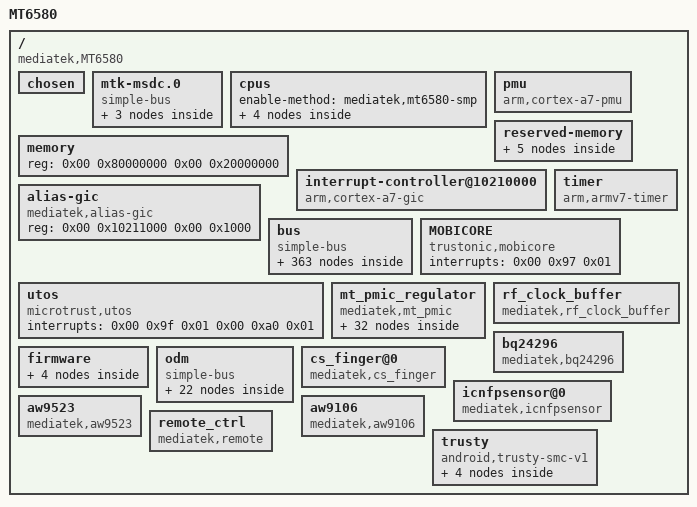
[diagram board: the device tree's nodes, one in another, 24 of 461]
/dts-v1/;

/ {
	model = "MT6580";
	compatible = "mediatek,MT6580";
	interrupt-parent = <0x01>;
	#address-cells = <0x02>;
	#size-cells = <0x02>;

	chosen {
		bootargs = "console=tty0 console=ttyMT0,921600n1 root=/dev/ram initrd=0x84000000,0x400000 loglevel=8";
		atag,videolfb-fb_base = <0x9e800000>;
		atag,videolfb-islcmfound = <0x01>;
		atag,videolfb-fps = <0x1770>;
		atag,videolfb-vramSize = <0x1800000>;
		atag,videolfb-lcmname = "nt35590_AUO";
		linux,phandle = <0x63>;
		phandle = <0x63>;
	};

	mtk-msdc.0 {
		compatible = "simple-bus";
		#address-cells = <0x01>;
		#size-cells = <0x01>;
		ranges = <0x00 0x00 0x00 0xffffffff>;

		msdc0@11120000 {
			compatible = "mediatek,mt6580-mmc";
			reg = <0x11120000 0x10000 0x10001e84 0x02>;
			interrupts = <0x00 0x26 0x08>;
			status = "okay";
			clk_src = [07];
			bus-width = <0x08>;
			max-frequency = <0xc65d400>;
			cap-mmc-highspeed;
			msdc-sys-suspend;
			mmc-hs200-1_8v;
			non-removable;
			pinctl = <0x02>;
			register_setting = <0x03>;
			host_function = [00];
			bootable;
			linux,phandle = <0x64>;
			phandle = <0x64>;
		};

		msdc1@11130000 {
			compatible = "mediatek,mt6580-mmc";
			reg = <0x11130000 0x10000 0x10001e84 0x02>;
			interrupts = <0x00 0x27 0x08>;
			cd-gpios = <0x04 0x14 0x00>;
			status = "okay";
			clk_src = [02];
			bus-width = <0x04>;
			max-frequency = <0xc65d400>;
			msdc-sys-suspend;
			cap-sd-highspeed;
			sd-uhs-sdr12;
			sd-uhs-sdr25;
			sd-uhs-sdr50;
			sd-uhs-sdr104;
			pinctrl-names = "default\0insert_cfg";
			pinctrl-0 = <0x05>;
			pinctrl-1 = <0x06>;
			pinctl = <0x07>;
			pinctl_sdr104 = <0x08>;
			pinctl_sdr50 = <0x09>;
			pinctl_ddr50 = <0x0a>;
			register_setting = <0x0b>;
			host_function = [01];
			cd_level = [00];
			linux,phandle = <0x65>;
			phandle = <0x65>;
		};

		default {
			compatible = "mediatek,msdc1_ins-eint";
			linux,phandle = <0x66>;
			phandle = <0x66>;
		};
	};

	cpus {
		#address-cells = <0x01>;
		#size-cells = <0x00>;
		enable-method = "mediatek,mt6580-smp";

		cpu@0 {
			device_type = "cpu";
			compatible = "arm,cortex-a7";
			reg = <0x00>;
			clock-frequency = <0x6553f100>;
			linux,phandle = <0x67>;
			phandle = <0x67>;
		};

		cpu@1 {
			device_type = "cpu";
			compatible = "arm,cortex-a7";
			reg = <0x01>;
			clock-frequency = <0x6553f100>;
			linux,phandle = <0x68>;
			phandle = <0x68>;
		};

		cpu@2 {
			device_type = "cpu";
			compatible = "arm,cortex-a7";
			reg = <0x02>;
			clock-frequency = <0x6553f100>;
			linux,phandle = <0x69>;
			phandle = <0x69>;
		};

		cpu@3 {
			device_type = "cpu";
			compatible = "arm,cortex-a7";
			reg = <0x03>;
			clock-frequency = <0x6553f100>;
			linux,phandle = <0x6a>;
			phandle = <0x6a>;
		};
	};

	pmu {
		compatible = "arm,cortex-a7-pmu";
		interrupts = <0x00 0x04 0x08 0x00 0x05 0x08 0x00 0x06 0x08 0x00 0x07 0x08>;
	};

	memory {
		device_type = "memory";
		reg = <0x00 0x80000000 0x00 0x20000000>;
	};

	reserved-memory {
		#address-cells = <0x02>;
		#size-cells = <0x02>;
		ranges;
		linux,phandle = <0x6b>;
		phandle = <0x6b>;

		consys-reserve-memory {
			compatible = "mediatek,consys-reserve-memory";
			no-map;
			size = <0x00 0x200000>;
			alignment = <0x00 0x200000>;
		};

		reserve-memory-ccci_md1 {
			compatible = "mediatek,reserve-memory-ccci_md1";
			no-map;
			size = <0x00 0x1800000>;
			alignment = <0x00 0x2000000>;
			alloc-ranges = <0x00 0x80000000 0x00 0x80000000>;
		};

		pstore-reserved-memory@83f10000 {
			compatible = "mediatek,pstore";
			reg = <0x00 0x83f10000 0x00 0xe0000>;
		};

		ram_console-reserved-memory@83f00000 {
			compatible = "mediatek,ram_console";
			reg = <0x00 0x83f00000 0x00 0x10000>;
		};

		minirdump-reserved-memory@83ff0000 {
			compatible = "mediatek, minirdump";
			reg = <0x00 0x83ff0000 0x00 0x10000>;
		};
	};

	interrupt-controller@10210000 {
		compatible = "arm,cortex-a7-gic";
		#interrupt-cells = <0x03>;
		#address-cells = <0x00>;
		interrupt-controller;
		reg = <0x00 0x10211000 0x00 0x1000 0x00 0x10212000 0x00 0x1000 0x00 0x10200100 0x00 0x1000>;
		interrupts = <0x01 0x09 0xf04>;
		linux,phandle = <0x01>;
		phandle = <0x01>;
	};

	alias-gic {
		compatible = "mediatek,alias-gic";
		reg = <0x00 0x10211000 0x00 0x1000>;
	};

	timer {
		compatible = "arm,armv7-timer";
		interrupts = <0x01 0x0d 0x08 0x01 0x0e 0x08 0x01 0x0b 0x08 0x01 0x0a 0x08>;
		clock-frequency = <0xc65d40>;
	};

	bus {
		compatible = "simple-bus";
		#address-cells = <0x01>;
		#size-cells = <0x01>;
		ranges = <0x00 0x00 0x00 0xffffffff>;
		linux,phandle = <0x6c>;
		phandle = <0x6c>;

		chipid@08000000 {
			compatible = "mediatek,chipid";
			reg = <0x8000000 0x04 0x8000004 0x04 0x8000008 0x04 0x800000c 0x04>;
		};

		TOPCKGEN@0x10000000 {
			compatible = "mediatek,TOPCKGEN";
			reg = <0x10000000 0x1000>;
		};

		INFRACFG_AO@0x10001000 {
			compatible = "mediatek,INFRACFG_AO";
			reg = <0x10001000 0x1000>;
		};

		bat_meter {
			compatible = "mediatek,bat_meter";
			linux,phandle = <0x6d>;
			phandle = <0x6d>;
		};

		BAT_NOTIFY {
			compatible = "mediatek,bat_notify";
		};

		bat_comm {
			compatible = "mediatek,battery";
			linux,phandle = <0x6e>;
			phandle = <0x6e>;
		};

		keypad@10002000 {
			compatible = "mediatek,mt6580-keypad";
			reg = <0x10002000 0x1000>;
			interrupts = <0x00 0x6d 0x02>;
			mediatek,kpd-key-debounce = <0x400>;
			mediatek,kpd-sw-pwrkey = <0x74>;
			mediatek,kpd-hw-pwrkey = <0x08>;
			mediatek,kpd-sw-rstkey = <0x66>;
			mediatek,kpd-hw-rstkey = <0x11>;
			mediatek,kpd-use-extend-type = <0x00>;
			mediatek,kpd-hw-map-num = <0x48>;
			mediatek,kpd-hw-init-map = <0x00 0x00 0x00 0x00 0x00 0x00 0x00 0x00 0x00 0x00 0x00 0x00 0x00 0x00 0x00 0x00 0x00 0x00 0x9e 0x66 0x8b 0x72 0x73 0x00 0x00 0x00 0x00 0x67 0x6c 0x69 0x6a 0x1c 0x00 0x00 0x00 0x00 0x00 0x00 0x00 0x00 0x00 0x00 0x00 0x00 0x00 0x00 0x00 0x00 0x00 0x00 0x00 0x00 0x00 0x00 0x00 0x00 0x00 0x00 0x00 0x00 0x00 0x00 0x00 0x00 0x00 0x00 0x00 0x00 0x00 0x00 0x00 0x00>;
			mediatek,kpd-pwrkey-eint-gpio = <0x00>;
			mediatek,kpd-pwkey-gpio-din = <0x00>;
			mediatek,kpd-hw-dl-key0 = <0x16>;
			mediatek,kpd-hw-dl-key1 = <0x15>;
			mediatek,kpd-hw-dl-key2 = <0x08>;
			mediatek,kpd-hw-recovery-key = <0x16>;
			mediatek,kpd-hw-factory-key = <0x15>;
			status = "okay";
			linux,phandle = <0x6f>;
			phandle = <0x6f>;
		};

		PERICFG@0x10003000 {
			compatible = "mediatek,PERICFG";
			reg = <0x10003000 0x1000>;
		};

		RESERVED@0x10004000 {
			compatible = "mediatek,RESERVED";
			reg = <0x10004000 0x1000>;
		};

		gpio {
			compatible = "mediatek,gpio_usage_mapping";
			GPIO_SIM1_SCLK = <0x16>;
			GPIO_SIM1_SIO = <0x17>;
			GPIO_SIM2_SIO = <0x18>;
			GPIO_SIM2_SCLK = <0x19>;
			linux,phandle = <0x70>;
			phandle = <0x70>;
		};

		gpio@0x10005000 {
			compatible = "mediatek,gpio";
			reg = <0x10005000 0x1000>;
			linux,phandle = <0x71>;
			phandle = <0x71>;
		};

		SLEEP@0x10006000 {
			compatible = "mediatek,SLEEP";
			reg = <0x10006000 0x1000>;
			interrupts = <0x00 0x58 0x08 0x00 0x59 0x08 0x00 0x5a 0x08 0x00 0x5b 0x08>;
		};

		TOPRGU@0x10007000 {
			compatible = "mediatek,TOPRGU";
			reg = <0x10007000 0x1000>;
			interrupts = <0x00 0x9d 0x02>;
		};

		APXGPT@0x10008000 {
			compatible = "mediatek,APXGPT";
			reg = <0x10008000 0x1000>;
			interrupts = <0x00 0x5c 0x08>;
			clock-frequency = <0xc65d40>;
		};

		EFUSEC@0x10009000 {
			compatible = "mediatek,EFUSEC";
			reg = <0x10009000 0x1000>;
		};

		hacc@0x1000A000 {
			compatible = "mediatek,hacc";
			reg = <0x1000a000 0x1000>;
			interrupts = <0x00 0x6e 0x00>;
		};

		cpu_dbgapb@10170000 {
			compatible = "mediatek,hw_dbg";
			num = <0x04>;
			reg = <0x10170000 0x2000 0x10172000 0x2000 0x10174000 0x2000 0x10176000 0x2000>;
			linux,phandle = <0x72>;
			phandle = <0x72>;
		};

		eintc@1000b000 {
			compatible = "mediatek,mt-eic";
			reg = <0x1000b000 0x1000>;
			interrupts = <0x00 0x5e 0x04>;
			#interrupt-cells = <0x02>;
			interrupt-controller;
			mediatek,max_eint_num = <0x1a>;
			mediatek,mapping_table_entry = <0x53>;
			mediatek,mapping_table = <0x00 0x00 0x01 0x01 0x02 0x02 0x03 0x03 0x04 0x04 0x05 0x05 0x06 0x06 0x07 0x07 0x08 0x08 0x09 0x09 0x0a 0x0a 0x0b 0x0b 0x0c 0x0c 0x0d 0x0d 0x0e 0x0e 0x0f 0x0f 0x10 0x00 0x11 0x01 0x12 0x02 0x13 0x03 0x14 0x04 0x15 0x05 0x16 0x06 0x17 0x07 0x18 0x08 0x19 0x09 0x1a 0x0a 0x1b 0x0b 0x1c 0x0c 0x1d 0x0d 0x1e 0x0e 0x1f 0x0f 0x20 0x00 0x21 0x01 0x22 0x02 0x23 0x03 0x24 0x04 0x25 0x05 0x26 0x06 0x27 0x07 0x28 0x08 0x29 0x09 0x2a 0x0a 0x2b 0x0b 0x2c 0x0c 0x2d 0x0d 0x2e 0x0e 0x2f 0x0f 0x30 0x00 0x31 0x01 0x32 0x02 0x33 0x03 0x34 0x03 0x35 0x04 0x36 0x05 0x37 0x06 0x38 0x07 0x39 0x08 0x3a 0x0a 0x3b 0x0b 0x3c 0x0c 0x3d 0x0d 0x3e 0x0e 0x3f 0x0f 0x40 0x00 0x41 0x01 0x42 0x02 0x43 0x03 0x44 0x10 0x45 0x04 0x46 0x05 0x47 0x06 0x48 0x07 0x49 0x08 0x4a 0x09 0x4b 0x0a 0x4c 0x0b 0x4d 0x0c 0x4e 0x0d 0x51 0x00 0x52 0x01 0x53 0x02 0x54 0x03>;
			mediatek,builtin_entry = <0x0b>;
			mediatek,builtin_mapping = <0x00 0x03 0x14 0x01 0x03 0x12 0x07 0x04 0x14 0x08 0x04 0x12 0x09 0x03 0x14 0x0a 0x03 0x12 0x18 0x05 0x14 0x19 0x05 0x12 0x4d 0x02 0x14 0x4e 0x02 0x12 0x0d 0x01 0x11>;
			linux,phandle = <0x0c>;
			phandle = <0x0c>;

			pmic@13 {
				compatible = "mediatek, pmic-eint";
				interrupt-parent = <0x0c>;
				interrupts = <0x0d 0x04>;
				debounce = <0x0d 0x3e8>;
			};
		};

		ap_ccif0@1000C000 {
			compatible = "mediatek,ap_ccif0";
			reg = <0x1000c000 0x1000 0x1000d000 0x1000>;
			interrupts = <0x00 0x5d 0x08 0x00 0x98 0x02>;
			mediatek,ccif_capability = <0x02>;
			mediatek,md_smem_size = <0x200000>;
			linux,phandle = <0x73>;
			phandle = <0x73>;
		};

		MCUSYS_CFGREG@0x1020000 {
			compatible = "mediatek,MCUSYS_CFGREG_BASE";
			reg = <0x1020000 0x200>;
		};

		mcucfg@10200000 {
			compatible = "mediatek,mt6580-mcucfg";
			reg = <0x10200000 0x200>;
			linux,phandle = <0x74>;
			phandle = <0x74>;
		};

		AES@0x1000E000 {
			compatible = "mediatek,AES";
			reg = <0x1000e000 0x1000>;
		};

		PWRAP@0x1000F000 {
			compatible = "mediatek,PWRAP";
			reg = <0x1000f000 0x1000>;
			interrupts = <0x00 0x6c 0x00>;
		};

		DEVAPC_AO@0x10010000 {
			compatible = "mediatek,DEVAPC_AO";
			reg = <0x10010000 0x1000>;
		};

		MIPI_CONFG@0x10011000 {
			compatible = "mediatek,MIPI_CONFG";
			reg = <0x10011000 0x1000>;
		};

		INFRA_MBIST@0x10012000 {
			compatible = "mediatek,INFRA_MBIST";
			reg = <0x10012000 0x1000>;
		};

		RESERVED@0x10013000 {
			compatible = "mediatek,RESERVED";
			reg = <0x10013000 0x1000>;
		};

		IOCFG_T@0x10014000 {
			compatible = "mediatek,IOCFG_T";
			reg = <0x10014000 0x1000>;
		};

		IOCFG_B@0x10015000 {
			compatible = "mediatek,IOCFG_B";
			reg = <0x10015000 0x1000>;
		};

		IOCFG_L@0x10016000 {
			compatible = "mediatek,IOCFG_L";
			reg = <0x10016000 0x1000>;
		};

		IOCFG_R@0x10017000 {
			compatible = "mediatek,IOCFG_R";
			reg = <0x10017000 0x1000>;
		};

		APMIXED@0x10018000 {
			compatible = "mediatek,APMIXED";
			reg = <0x10018000 0x1000>;
		};

		MCUCFG@0x10200000 {
			compatible = "mediatek,MCUCFG";
			reg = <0x10200000 0x1000>;
		};

		INFRACFG@0x10201000 {
			compatible = "mediatek,INFRACFG";
			reg = <0x10201000 0x1000>;
		};

		sys_cirq@10202000 {
			compatible = "mediatek,mt6580-sys_cirq\0mediatek,mt6735-sys_cirq";
			reg = <0x10202000 0x1000>;
			interrupts = <0x00 0x9e 0x08>;
			mediatek,cirq_num = <0x7e>;
			mediatek,spi_start_offset = <0x20>;
			linux,phandle = <0x75>;
			phandle = <0x75>;
		};

		m4u@10203000 {
			cell-index = <0x00>;
			compatible = "mediatek,m4u";
			reg = <0x10203000 0x1000>;
			interrupts = <0x00 0x51 0x08>;
		};

		DEVAPC@0x10204000 {
			compatible = "mediatek,DEVAPC";
			reg = <0x10204000 0x1000>;
			interrupts = <0x00 0x4a 0x08>;
		};

		EMI@0x10205000 {
			compatible = "mediatek,EMI";
			reg = <0x10205000 0x1000>;
			interrupts = <0x00 0x4c 0x04>;
		};

		DRAMC_NAO@0x10206000 {
			compatible = "mediatek,DRAMC_NAO";
			reg = <0x10206000 0x1000>;
		};

		DRAMC0@0x10207000 {
			compatible = "mediatek,DRAMC0";
			reg = <0x10207000 0x1000>;
		};

		DDRPHY@0x10208000 {
			compatible = "mediatek,DDRPHY";
			reg = <0x10208000 0x1000>;
		};

		SRAMROM@0x10209000 {
			compatible = "mediatek,SRAMROM";
			reg = <0x10209000 0x1000>;
		};

		gce@1020a000 {
			compatible = "mediatek,gce";
			reg = <0x1020a000 0x1000>;
			interrupts = <0x00 0x55 0x08 0x00 0x56 0x08>;
			disp_mutex_reg = <0x14015000 0x1000>;
			g3d_config_base = <0x13000000 0x00 0xffff0000>;
			mmsys_config_base = <0x14000000 0x01 0xffff0000>;
			disp_dither_base = <0x14010000 0x02 0xffff0000>;
			mm_na_base = <0x14020000 0x03 0xffff0000>;
			imgsys_base = <0x15000000 0x04 0xffff0000>;
			vdec_gcon_base = <0x16000000 0x05 0xffff0000>;
			venc_gcon_base = <0x17000000 0x06 0xffff0000>;
			conn_peri_base = <0x18000000 0x07 0xffff0000>;
			topckgen_base = <0x10000000 0x08 0xffff0000>;
			kp_base = <0x10010000 0x09 0xffff0000>;
			scp_sram_base = <0x10020000 0x0a 0xffff0000>;
			infra_na3_base = <0x10030000 0x0b 0xffff0000>;
			infra_na4_base = <0x10040000 0x0c 0xffff0000>;
			scp_base = <0x10050000 0x0d 0xffff0000>;
			mcucfg_base = <0x10200000 0x0e 0xffff0000>;
			gcpu_base = <0x10210000 0x0f 0xffff0000>;
			usb0_base = <0x11200000 0x10 0xffff0000>;
			usb_sif_base = <0x11210000 0x11 0xffff0000>;
			audio_base = <0x11220000 0x12 0xffff0000>;
			msdc0_base = <0x11230000 0x13 0xffff0000>;
			msdc1_base = <0x11240000 0x14 0xffff0000>;
			msdc2_base = <0x11250000 0x15 0xffff0000>;
			msdc3_base = <0x11260000 0x16 0xffff0000>;
			pwm_sw_base = <0x1100f000 0x63 0xfffff000>;
			mdp_rdma0_sof = <0x00>;
			mdp_rsz0_sof = <0x01>;
			mdp_rsz1_sof = <0x02>;
			mdp_tdshp_sof = <0x03>;
			mdp_wdma_sof = <0x04>;
			mdp_wrot_sof = <0x05>;
			disp_ovl0_sof = <0x06>;
			disp_rdma0_sof = <0x08>;
			disp_wdma0_sof = <0x0a>;
			disp_color_sof = <0x0c>;
			disp_aal_sof = <0x0d>;
			disp_gamma_sof = <0x0e>;
			disp_dither_sof = <0x0f>;
			disp_pwm0_sof = <0x11>;
			mdp_rdma0_frame_done = <0x12>;
			mdp_rsz0_frame_done = <0x13>;
			mdp_rsz1_frame_done = <0x14>;
			mdp_tdshp_frame_done = <0x15>;
			mdp_wdma_frame_done = <0x16>;
			mdp_wrot_write_frame_done = <0x17>;
			mdp_wrot_read_frame_done = <0x18>;
			disp_ovl0_frame_done = <0x19>;
			disp_rdma0_frame_done = <0x1b>;
			disp_wdma0_frame_done = <0x1d>;
			disp_color_frame_done = <0x1f>;
			disp_aal_frame_done = <0x20>;
			disp_gamma_frame_done = <0x21>;
			disp_dither_frame_done = <0x22>;
			disp_dsi0_frame_done = <0x25>;
			stream_done_0 = <0x26>;
			stream_done_1 = <0x27>;
			stream_done_2 = <0x28>;
			stream_done_3 = <0x29>;
			stream_done_4 = <0x2a>;
			stream_done_5 = <0x2b>;
			stream_done_6 = <0x2c>;
			stream_done_7 = <0x2d>;
			stream_done_8 = <0x2e>;
			stream_done_9 = <0x2f>;
			buf_underrun_event_0 = <0x30>;
			dsi0_te_event = <0x32>;
			isp_frame_done_p2_1 = <0x42>;
			isp_frame_done_p2_0 = <0x43>;
			seninf_cam0_fifo_full = <0x49>;
			apxgpt2_count = <0x10008028>;
		};

		bus_dbg@1020b000 {
			compatible = "mediatek,bus_dbg-v2";
			reg = <0x1020b000 0x1000>;
			interrupts = <0x00 0x49 0x08>;
			two_stage_timeout = <0x01>;
		};

		TRNG@0x1020C000 {
			compatible = "mediatek,TRNG";
			reg = <0x1020c000 0x1000>;
			interrupts = <0x00 0x57 0x08>;
		};

		MCUCFG_BIU@0x1020D000 {
			compatible = "mediatek,MCUCFG_BIU";
			reg = <0x1020d000 0x1000>;
		};

		DBGSYS_DEM@0x1011A000 {
			compatible = "mediatek,DBGSYS_DEM";
			reg = <0x1011a000 0x1000>;
		};

		DBGSYS_CTI@0x10112000 {
			compatible = "mediatek,DBGSYS_CTI";
			reg = <0x10112000 0x1000>;
		};

		DBGSYS_DAPROM@0x10110000 {
			compatible = "mediatek,DBGSYS_DAPROM";
			reg = <0x10110000 0x1000>;
		};

		DBGSYS_CPU@0x10160000 {
			compatible = "mediatek,DBGSYS_CPU";
			reg = <0x10160000 0x20000>;
		};

		DBGSYS_MDSYS@0x10120000 {
			compatible = "mediatek,DBGSYS_MDSYS";
			reg = <0x10120000 0x10000>;
		};

		dma@0x11000000 {
			compatible = "mediatek,ap_dma";
			reg = <0x11000000 0x1000>;
			interrupts = <0x00 0x30 0x08>;
			linux,phandle = <0x76>;
			phandle = <0x76>;
		};

		NFI@0x11001000 {
			compatible = "mediatek,NFI";
			reg = <0x11001000 0x1000>;
			interrupts = <0x00 0x2f 0x08>;
		};

		NFIECC@0x11002000 {
			compatible = "mediatek,NFIECC";
			reg = <0x11002000 0x1000>;
			interrupts = <0x00 0x2e 0x08>;
		};

		adc_hw@11003000 {
			compatible = "mediatek,mt6735-auxadc";
			reg = <0x11003000 0x1000>;
			interrupts = <0x00 0x23 0x02>;
			linux,phandle = <0x77>;
			phandle = <0x77>;

			adc_channel@ {
				compatible = "mediatek,adc_channel";
				mediatek,temperature0 = <0x00>;
				mediatek,temperature1 = <0x01>;
				status = "okay";
			};
		};

		FHCTL@0x11004000 {
			compatible = "mediatek,FHCTL";
			reg = <0x11004000 0x1000>;
		};

		AP_UART0@0x11005000 {
			cell-index = <0x00>;
			compatible = "mediatek,AP_UART0";
			reg = <0x11005000 0x1000>;
			interrupts = <0x00 0x2c 0x08>;
		};

		AP_UART1@0x11006000 {
			cell-index = <0x01>;
			compatible = "mediatek,AP_UART1";
			reg = <0x11006000 0x1000>;
			interrupts = <0x00 0x2d 0x08>;
		};

		AP_DMA_UART0_TX@0x11000480 {
			compatible = "mediatek,AP_DMA_UART0_TX";
			reg = <0x11000480 0x80>;
			interrupts = <0x00 0x38 0x08>;
		};

		AP_DMA_UART0_RX@0x11000500 {
			compatible = "mediatek,AP_DMA_UART0_RX";
			reg = <0x11000500 0x80>;
			interrupts = <0x00 0x39 0x08>;
		};

		AP_DMA_UART1_TX@0x11000580 {
			compatible = "mediatek,AP_DMA_UART1_TX";
			reg = <0x11000580 0x80>;
			interrupts = <0x00 0x3a 0x08>;
		};

		AP_DMA_UART1_RX@0x11000600 {
			compatible = "mediatek,AP_DMA_UART1_RX";
			reg = <0x11000600 0x80>;
			interrupts = <0x00 0x3b 0x08>;
		};

		PWM@0x11008000 {
			compatible = "mediatek,PWM";
			reg = <0x11008000 0x1000>;
			interrupts = <0x00 0x24 0x08>;
		};

		syscfg_pctl_a@0x10005000 {
			compatible = "mediatek,mt6580-pctl-a-syscfg\0syscon";
			reg = <0x10211000 0x1000>;
			linux,phandle = <0x0d>;
			phandle = <0x0d>;
		};

		pinctrl@0x10005000 {
			compatible = "mediatek,mt6580-pinctrl";
			reg = <0x10005000 0x1000>;
			mediatek,pctl-regmap = <0x0d>;
			pins-are-numbered;
			gpio-controller;
			#gpio-cells = <0x02>;
			linux,phandle = <0x04>;
			phandle = <0x04>;

			mmc0@default {
				linux,phandle = <0x02>;
				phandle = <0x02>;

				pins_cmd {
					drive-strength = [02];
				};

				pins_dat {
					drive-strength = [02];
				};

				pins_clk {
					drive-strength = [02];
				};

				pins_rst {
					drive-strength = [02];
				};

				pins_ds {
					drive-strength = [02];
				};
			};

			mmc0@register_default {
				dat0rddly = [00];
				dat1rddly = [00];
				dat2rddly = [00];
				dat3rddly = [00];
				dat4rddly = [00];
				dat5rddly = [00];
				dat6rddly = [00];
				dat7rddly = [00];
				datwrddly = [00];
				cmdrrddly = [00];
				cmdrddly = [00];
				cmd_edge = [01];
				rdata_edge = [01];
				wdata_edge = [01];
				ett-hs200-cells = <0x0c>;
				ett-hs200-default = <0xb0 0x380 0x00 0xb0 0x7c00 0x00 0xb4 0x38 0x01 0x04 0x02 0x01 0xf0 0x1f0000 0x00 0xf0 0x7c00000 0x00 0xb4 0x07 0x01 0xf0 0x1f 0x00 0x04 0x100 0x01 0xf8 0x1f000000 0x00 0xf0 0x1f00 0x00 0xb0 0x08 0x01>;
				linux,phandle = <0x03>;
				phandle = <0x03>;
			};

			mmc1@default {
				linux,phandle = <0x07>;
				phandle = <0x07>;

				pins_cmd {
					drive-strength = [03];
				};

				pins_dat {
					drive-strength = [03];
				};

				pins_clk {
					drive-strength = [03];
				};
			};

			mmc1_ins_default {
				linux,phandle = <0x05>;
				phandle = <0x05>;
			};

			mmc1_ins_cfg {
				linux,phandle = <0x06>;
				phandle = <0x06>;

				pins_insert {
					pins = <0x1406>;
					input-schmitt-enable = <0x01>;
					slew-rate = <0x00>;
					bias-pull-up = <0x00>;
				};
			};

			mmc1@sdr104 {
				linux,phandle = <0x08>;
				phandle = <0x08>;

				pins_cmd {
					drive-strength = [02];
				};

				pins_dat {
					drive-strength = [02];
				};

				pins_clk {
					drive-strength = [03];
				};
			};

			mmc1@sdr50 {
				linux,phandle = <0x09>;
				phandle = <0x09>;

				pins_cmd {
					drive-strength = [02];
				};

				pins_dat {
					drive-strength = [02];
				};

				pins_clk {
					drive-strength = [03];
				};
			};

			mmc1@ddr50 {
				linux,phandle = <0x0a>;
				phandle = <0x0a>;

				pins_cmd {
					drive-strength = [02];
				};

				pins_dat {
					drive-strength = [02];
				};

				pins_clk {
					drive-strength = [03];
				};
			};

			mmc1@register_default {
				dat0rddly = [00];
				dat1rddly = [00];
				dat2rddly = [00];
				dat3rddly = [00];
				datwrddly = [00];
				cmdrrddly = [00];
				cmdrddly = [00];
				cmd_edge = [01];
				rdata_edge = [01];
				wdata_edge = [01];
				linux,phandle = <0x0b>;
				phandle = <0x0b>;
			};

			alspspincfg {
				linux,phandle = <0x0f>;
				phandle = <0x0f>;

				pins_cmd_dat {
					pins = <0x606>;
					slew-rate = <0x00>;
					bias-pull-up = <0x00>;
				};
			};

			alspsdefaultcfg {
				linux,phandle = <0x0e>;
				phandle = <0x0e>;
			};

			eint0default {
				linux,phandle = <0x17>;
				phandle = <0x17>;
			};

			eint@0 {
				linux,phandle = <0x18>;
				phandle = <0x18>;

				pins_cmd_dat {
					pins = <0x306>;
					slew-rate = <0x00>;
					bias-disable;
				};
			};

			toucheint5default {
				linux,phandle = <0x11>;
				phandle = <0x11>;
			};

			toucheint@5 {
				linux,phandle = <0x12>;
				phandle = <0x12>;

				pins_cmd_dat {
					pins = <0x506>;
					slew-rate = <0x00>;
					bias-disable;
				};
			};

			eintoutput0 {
				linux,phandle = <0x13>;
				phandle = <0x13>;

				pins_cmd_dat {
					pins = <0x500>;
					slew-rate = <0x01>;
					output-low;
				};
			};

			eintoutput1 {
				linux,phandle = <0x14>;
				phandle = <0x14>;

				pins_cmd_dat {
					pins = <0x500>;
					slew-rate = <0x01>;
					output-high;
				};
			};

			rstoutput0 {
				linux,phandle = <0x15>;
				phandle = <0x15>;

				pins_cmd_dat {
					pins = <0x200>;
					slew-rate = <0x01>;
					output-low;
				};
			};

			rstoutput1 {
				linux,phandle = <0x16>;
				phandle = <0x16>;

				pins_cmd_dat {
					pins = <0x200>;
					slew-rate = <0x01>;
					output-high;
				};
			};

			audiodefault {
				linux,phandle = <0x23>;
				phandle = <0x23>;
			};

			pmicclkmode0 {
				linux,phandle = <0x24>;
				phandle = <0x24>;

				pins_cmd0_dat {
					pins = <0x1a00>;
				};

				pins_cmd1_dat {
					pins = <0x1c00>;
				};

				pins_cmd2_dat {
					pins = <0x1b00>;
				};
			};

			pmicclkmode1 {
				linux,phandle = <0x25>;
				phandle = <0x25>;

				pins_cmd0_dat {
					pins = <0x1a01>;
				};

				pins_cmd1_dat {
					pins = <0x1c01>;
				};

				pins_cmd2_dat {
					pins = <0x1b01>;
				};
			};

			mode_te_gpio {
				linux,phandle = <0x3c>;
				phandle = <0x3c>;

				pins_cmd_dat {
					pins = <0x4400>;
				};
			};

			mode_te_te {
				linux,phandle = <0x3d>;
				phandle = <0x3d>;

				pins_cmd_dat {
					pins = <0x4401>;
				};
			};

			lcm_rst_out0_gpio {
				linux,phandle = <0x3e>;
				phandle = <0x3e>;

				pins_cmd_dat {
					pins = <0x4601>;
					slew-rate = <0x01>;
					output-low;
				};
			};

			lcm_rst_out1_gpio {
				linux,phandle = <0x3f>;
				phandle = <0x3f>;

				pins_cmd_dat {
					pins = <0x4601>;
					slew-rate = <0x01>;
					output-high;
				};
			};

			pwm_test_pin_mux_gpio66 {
				linux,phandle = <0x40>;
				phandle = <0x40>;

				pins_cmd_dat {
					pins = <0x4201>;
					slew-rate = <0x01>;
				};
			};

			mtkfb_default {
				linux,phandle = <0x3b>;
				phandle = <0x3b>;
			};

			cam0@0 {
				linux,phandle = <0x2b>;
				phandle = <0x2b>;

				pins_cmd_dat {
					pins = <0x4900>;
					slew-rate = <0x01>;
					output-low;
				};
			};

			cam0@1 {
				linux,phandle = <0x2c>;
				phandle = <0x2c>;

				pins_cmd_dat {
					pins = <0x4900>;
					slew-rate = <0x01>;
					output-high;
				};
			};

			cam0@2 {
				linux,phandle = <0x2d>;
				phandle = <0x2d>;

				pins_cmd_dat {
					pins = <0x4700>;
					slew-rate = <0x01>;
					output-low;
				};
			};

			cam0@3 {
				linux,phandle = <0x2e>;
				phandle = <0x2e>;

				pins_cmd_dat {
					pins = <0x4700>;
					slew-rate = <0x01>;
					output-high;
				};
			};

			cam1@0 {
				linux,phandle = <0x2f>;
				phandle = <0x2f>;

				pins_cmd_dat {
					pins = <0x4c00>;
					slew-rate = <0x01>;
					output-low;
				};
			};

			cam1@1 {
				linux,phandle = <0x30>;
				phandle = <0x30>;

				pins_cmd_dat {
					pins = <0x4c00>;
					slew-rate = <0x01>;
					output-high;
				};
			};

			cam1@2 {
				linux,phandle = <0x31>;
				phandle = <0x31>;

				pins_cmd_dat {
					pins = <0x4a00>;
					slew-rate = <0x01>;
					output-low;
				};
			};

			cam1@3 {
				linux,phandle = <0x32>;
				phandle = <0x32>;

				pins_cmd_dat {
					pins = <0x4a00>;
					slew-rate = <0x01>;
					output-high;
				};
			};

			cam@0 {
				linux,phandle = <0x33>;
				phandle = <0x33>;
			};

			cam@1 {
				linux,phandle = <0x34>;
				phandle = <0x34>;
			};

			camdefault {
				linux,phandle = <0x2a>;
				phandle = <0x2a>;
			};

			cam1serial@0 {
				linux,phandle = <0x35>;
				phandle = <0x35>;

				pins_cmd_dat {
					pins = <0x2302>;
				};

				pins_cmd_dat1 {
					pins = <0x2402>;
				};

				pins_cmd_dat2 {
					pins = <0x2502>;
				};

				pins_cmd_dat3 {
					pins = <0x2602>;
				};

				pins_cmd_dat4 {
					pins = <0x2702>;
				};
			};

			cam1mipi@0 {
				linux,phandle = <0x36>;
				phandle = <0x36>;

				pins_cmd_dat {
					pins = <0x2301>;
				};

				pins_cmd_dat1 {
					pins = <0x2401>;
				};

				pins_cmd_dat2 {
					pins = <0x2501>;
				};

				pins_cmd_dat3 {
					pins = <0x2601>;
				};

				pins_cmd_dat4 {
					pins = <0x2701>;
				};

				pins_cmd_dat5 {
					pins = <0x2801>;
				};
			};

			mclk1enable@0 {
				linux,phandle = <0x37>;
				phandle = <0x37>;

				pins_cmd_dat {
					pins = <0x4b01>;
				};
			};

			mclk1disable@0 {
				linux,phandle = <0x38>;
				phandle = <0x38>;

				pins_cmd_dat {
					pins = <0x4b00>;
				};
			};

			mclk2enable@0 {
				linux,phandle = <0x39>;
				phandle = <0x39>;

				pins_cmd_dat {
					pins = <0x4b01>;
				};
			};

			mclk2disable@0 {
				linux,phandle = <0x3a>;
				phandle = <0x3a>;

				pins_cmd_dat {
					pins = <0x4b00>;
				};
			};

			consys_default {
				linux,phandle = <0x1d>;
				phandle = <0x1d>;
			};

			gpslna@0 {
				linux,phandle = <0x1e>;
				phandle = <0x1e>;

				pins_cmd_dat {
					pins = <0x1500>;
					slew-rate = <0x00>;
					bias-disable;
					output-low;
				};
			};

			gpslna@1 {
				linux,phandle = <0x1f>;
				phandle = <0x1f>;

				pins_cmd_dat {
					pins = <0x1500>;
					slew-rate = <0x01>;
					output-high;
				};
			};

			gpslna@2 {
				linux,phandle = <0x20>;
				phandle = <0x20>;

				pins_cmd_dat {
					pins = <0x1500>;
					slew-rate = <0x01>;
					output-low;
				};
			};

			aw@0 {
				linux,phandle = <0x55>;
				phandle = <0x55>;
			};

			aw@1 {
				linux,phandle = <0x56>;
				phandle = <0x56>;

				pins_cmd_dat {
					pins = <0x4800>;
					slew-rate = <0x01>;
					output-high;
				};
			};

			aw@2 {
				linux,phandle = <0x57>;
				phandle = <0x57>;

				pins_cmd_dat {
					pins = <0x4800>;
					slew-rate = <0x01>;
					output-low;
				};
			};

			www@0 {
				linux,phandle = <0x58>;
				phandle = <0x58>;
			};

			www@1 {
				linux,phandle = <0x59>;
				phandle = <0x59>;

				pins_cmd_dat {
					pins = <0x4900>;
					slew-rate = <0x01>;
					output-high;
				};
			};

			www@2 {
				linux,phandle = <0x5a>;
				phandle = <0x5a>;

				pins_cmd_dat {
					pins = <0x4900>;
					slew-rate = <0x01>;
					output-low;
				};
			};

			default {
				linux,phandle = <0x5b>;
				phandle = <0x5b>;
			};

			eint_in@0 {
				linux,phandle = <0x5c>;
				phandle = <0x5c>;

				pins_cmd_dat {
					pins = <0x4100>;
					slew-rate = <0x00>;
					bias-pull-up = <0x00>;
				};
			};

			eint_out@1 {
				linux,phandle = <0x5d>;
				phandle = <0x5d>;

				pins_cmd_dat {
					pins = <0x4100>;
					slew-rate = <0x01>;
					output-high;
				};
			};

			eint_out@2 {
				linux,phandle = <0x5e>;
				phandle = <0x5e>;

				pins_cmd_dat {
					pins = <0x4100>;
					slew-rate = <0x01>;
					output-low;
				};
			};

			rst_out@0 {
				linux,phandle = <0x5f>;
				phandle = <0x5f>;

				pins_cmd_dat {
					pins = <0x4500>;
					slew-rate = <0x01>;
					output-high;
				};
			};

			rst_out@1 {
				linux,phandle = <0x60>;
				phandle = <0x60>;

				pins_cmd_dat {
					pins = <0x4500>;
					slew-rate = <0x01>;
					output-low;
				};
			};

			vdd_en@0 {
				linux,phandle = <0x61>;
				phandle = <0x61>;

				pins_cmd_dat {
					pins = <0x4300>;
					slew-rate = <0x01>;
					output-high;
				};
			};

			vdd_en@1 {
				linux,phandle = <0x62>;
				phandle = <0x62>;

				pins_cmd_dat {
					pins = <0x4300>;
					slew-rate = <0x01>;
					output-low;
				};
			};

			bq24296_default {
				linux,phandle = <0x52>;
				phandle = <0x52>;
			};

			drvvbus_low {
				linux,phandle = <0x53>;
				phandle = <0x53>;

				pins_cmd_dat {
					pins = <0x4c00>;
					slew-rate = <0x01>;
					output-low;
				};
			};

			drvvbus_high {
				linux,phandle = <0x54>;
				phandle = <0x54>;

				pins_cmd_dat {
					pins = <0x4c00>;
					slew-rate = <0x01>;
					output-high;
				};
			};

			usb_default {
				linux,phandle = <0x21>;
				phandle = <0x21>;
			};

			iddig_irq_init {
				linux,phandle = <0x22>;
				phandle = <0x22>;

				pins_cmd_dat {
					pins = <0x06>;
					slew-rate = <0x00>;
					bias-pull-up = <0x00>;
				};
			};
		};

		i2c@11009000 {
			compatible = "mediatek,mt6580-i2c\0mediatek,i2c0";
			cell-index = <0x00>;
			reg = <0x11009000 0x1000>;
			interrupts = <0x00 0x28 0x08 0x00 0x32 0x08>;
			clock-div = <0x0a>;
			#address-cells = <0x01>;
			#size-cells = <0x00>;
			linux,phandle = <0x78>;
			phandle = <0x78>;

			bq24296@6b {
				compatible = "mediatek,bq24296";
				reg = <0x6b>;
				status = "okay";
				linux,phandle = <0x79>;
				phandle = <0x79>;
			};

			camera_main@12 {
				compatible = "mediatek,camera_main";
				reg = <0x12>;
				status = "okay";
				linux,phandle = <0x7a>;
				phandle = <0x7a>;
			};

			camera_sub@14 {
				compatible = "mediatek,camera_sub";
				reg = <0x14>;
				status = "okay";
				linux,phandle = <0x7b>;
				phandle = <0x7b>;
			};

			remote_ctrl@10 {
				compatible = "mediatek,remote_ctrl";
				reg = <0x10>;
				status = "okay";
				linux,phandle = <0x7c>;
				phandle = <0x7c>;
			};
		};

		i2c@1100a000 {
			compatible = "mediatek,mt6580-i2c\0mediatek,i2c1";
			cell-index = <0x01>;
			reg = <0x1100a000 0x1000>;
			interrupts = <0x00 0x29 0x08 0x00 0x33 0x08>;
			clock-div = <0x0a>;
			#address-cells = <0x01>;
			#size-cells = <0x00>;
			linux,phandle = <0x7d>;
			phandle = <0x7d>;

			cap_touch@38 {
				compatible = "mediatek,cap_touch";
				reg = <0x38>;
				status = "okay";
				linux,phandle = <0x7e>;
				phandle = <0x7e>;
			};

			ext_gpio_aw9523@5b {
				compatible = "mediatek,ext_gpio_aw9523";
				reg = <0x5b>;
				status = "okay";
				linux,phandle = <0x7f>;
				phandle = <0x7f>;
			};
		};

		i2c@1100b000 {
			compatible = "mediatek,mt6580-i2c\0mediatek,i2c2";
			cell-index = <0x02>;
			reg = <0x1100b000 0x1000>;
			interrupts = <0x00 0x2a 0x08 0x00 0x34 0x08>;
			clock-div = <0x0a>;
			#address-cells = <0x01>;
			#size-cells = <0x00>;
			linux,phandle = <0x80>;
			phandle = <0x80>;

			gsensor@68 {
				i2c_num = <0x02>;
				i2c_addr = <0x68 0x00 0x00 0x00>;
				direction = <0x04>;
				power_id = <0xffff>;
				power_vol = <0x00>;
				firlen = <0x00>;
				is_batch_supported = <0x00>;
				compatible = "mediatek,gsensor";
				reg = <0x68>;
				status = "okay";
				linux,phandle = <0x81>;
				phandle = <0x81>;
			};

			msensor@0d {
				i2c_num = <0x02>;
				i2c_addr = <0x0d 0x00 0x00 0x00>;
				direction = <0x04>;
				power_id = <0xffff>;
				power_vol = <0x00>;
				is_batch_supported = <0x00>;
			};

			gyro@68 {
				i2c_num = <0x02>;
				i2c_addr = <0x68 0x00 0x00 0x00>;
				direction = <0x01>;
				power_id = <0xffff>;
				power_vol = <0x00>;
				firlen = <0x00>;
				is_batch_supported = <0x00>;
			};

			alsps@60 {
				pinctrl-names = "pin_default\0pin_cfg";
				pinctrl-0 = <0x0e>;
				pinctrl-1 = <0x0f>;
				status = "okay";
				i2c_num = <0x02>;
				i2c_addr = <0x60 0x00 0x00 0x00>;
				polling_mode_ps = <0x00>;
				polling_mode_als = <0x01>;
				power_id = <0xffff>;
				power_vol = <0x00>;
				als_level = <0x00 0x7d 0x13f 0x20d 0x443 0x9b0 0xbf2 0x13fb 0x218d 0x2a11 0x3239 0x458f 0x564b 0xffff 0xffff>;
				als_value = <0x00 0x85 0x12f 0x1f8 0x3ea 0x7d3 0xbbe 0x138b 0x1f42 0x2710 0x2ee0 0x3e80 0x4e20 0x4e20 0x4e20 0x4e20>;
				ps_threshold_high = <0x1a>;
				ps_threshold_low = <0x15>;
				is_batch_supported_ps = <0x00>;
				is_batch_supported_als = <0x00>;
			};

			flashlight@0 {
				compatible = "mediatek,kd_camera_flashlight";
				flashlight_main_mode_pin = <0x22>;
				flashlight_main_enable_pin = <0x54>;
				flashlight_main_flash_en_pin = <0xff>;
				flashlight_sub_mode_pin = <0xff>;
				flashlight_sub_enable_pin = <0xff>;
				flashlight_sub_flash_en_pin = <0x11>;
				status = "okay";
			};

			alsps@49 {
				compatible = "mediatek,alsps_epl259x";
				reg = <0x49>;
				status = "okay";
			};

			alsps@48 {
				compatible = "mediatek,alsps_stk3x1x";
				reg = <0x48>;
				status = "okay";
			};

			alsps@63 {
				compatible = "mediatek,alsps";
				reg = <0x63>;
				status = "okay";
				linux,phandle = <0x82>;
				phandle = <0x82>;
			};

			msensor@0c {
				compatible = "mediatek,msensor";
				reg = <0x0c>;
				status = "okay";
				linux,phandle = <0x83>;
				phandle = <0x83>;
			};

			gyro@69 {
				compatible = "mediatek,gyro";
				reg = <0x69>;
				status = "okay";
				linux,phandle = <0x84>;
				phandle = <0x84>;
			};

			ext_gpio_aw9106@5b {
				compatible = "mediatek,ext_gpio_aw9106";
				reg = <0x5b>;
				status = "okay";
				linux,phandle = <0x85>;
				phandle = <0x85>;
			};
		};

		touch@0 {
			compatible = "mediatek,mt6580-touch";
			vtouch-supply = <0x10>;
			tpd-resolution = <0x1e0 0x320>;
			use-tpd-button = <0x00>;
			tpd-key-num = <0x03>;
			tpd-key-local = <0x8b 0xac 0x9e 0x00>;
			tpd-key-dim-local = <0x5a 0x373 0x64 0x28 0xe6 0x373 0x64 0x28 0x172 0x373 0x64 0x28 0x00 0x00 0x00 0x00>;
			tpd-max-touch-num = <0x05>;
			tpd-filter-enable = <0x00>;
			tpd-filter-pixel-density = <0x7c>;
			tpd-filter-custom-prameters = <0x00 0x00 0x00 0x00 0x00 0x00 0x00 0x00 0x00 0x00 0x00 0x00>;
			tpd-filter-custom-speed = <0x00 0x00 0x00>;
			pinctrl-names = "default\0state_eint_as_int\0state_eint_output0\0state_eint_output1\0state_rst_output0\0state_rst_output1";
			pinctrl-0 = <0x11>;
			pinctrl-1 = <0x12>;
			pinctrl-2 = <0x13>;
			pinctrl-3 = <0x14>;
			pinctrl-4 = <0x15>;
			pinctrl-5 = <0x16>;
			status = "okay";
			interrupt-parent = <0x0c>;
			interrupts = <0x05 0x02>;
			debounce = <0x05 0x00>;
			linux,phandle = <0x86>;
			phandle = <0x86>;
		};

		accdet {
			compatible = "mediatek,mt6580-accdet";
			accdet-mic-vol = <0x07>;
			headset-mode-setting = <0x500 0x200 0x01 0x1f0 0x800 0x800 0x20>;
			accdet-plugout-debounce = <0x14>;
			accdet-mic-mode = <0x01>;
			headset-three-key-threshold = <0x00 0x5a 0xf0 0x1f4>;
			headset-four-key-threshold = <0x00 0x3c 0x7e 0xc9 0x1c2>;
			pinctrl-names = "default\0state_eint_as_int";
			pinctrl-0 = <0x17>;
			pinctrl-1 = <0x18>;
			status = "okay";
			interrupt-parent = <0x0c>;
			interrupts = <0x03 0x04>;
			debounce = <0x03 0x3e800>;
			linux,phandle = <0x87>;
			phandle = <0x87>;
		};

		remoteir {
			compatible = "mediatek,remoteir-eint";
			status = "disabled";
			linux,phandle = <0x88>;
			phandle = <0x88>;
		};

		gse_1 {
			compatible = "mediatek, gse_1-eint";
			status = "okay";
			interrupt-parent = <0x0c>;
			interrupts = <0x53 0x08>;
			debounce = <0x53 0x00>;
			linux,phandle = <0x89>;
			phandle = <0x89>;
		};

		spi@1100c000 {
			compatible = "mediatek,mt6580-spi";
			cell-index = <0x00>;
			reg = <0x1100c000 0x1000>;
			interrupts = <0x00 0x40 0x08>;
			mediatek,spi-padmacro = <0x00>;
		};

		THERM_CTRL@0x1100D000 {
			compatible = "mediatek,THERM_CTRL";
			reg = <0x1100d000 0x1000>;
			interrupts = <0x00 0x25 0x08>;
		};

		btif_tx@11000380 {
			compatible = "mediatek,btif_tx";
			reg = <0x11000380 0x80>;
			interrupts = <0x00 0x36 0x08>;
			linux,phandle = <0x8a>;
			phandle = <0x8a>;
		};

		btif_rx@11000400 {
			compatible = "mediatek,btif_rx";
			reg = <0x11000400 0x80>;
			interrupts = <0x00 0x37 0x08>;
			linux,phandle = <0x8b>;
			phandle = <0x8b>;
		};

		btif@1100e000 {
			compatible = "mediatek,btif";
			reg = <0x1100e000 0x1000>;
			interrupts = <0x00 0x43 0x08>;
			linux,phandle = <0x8c>;
			phandle = <0x8c>;
		};

		gps {
			compatible = "mediatek,gps";
		};

		BTCVSD@0x10001000 {
			compatible = "mediatek,audio_bt_cvsd";
			offset = <0xc00 0x02 0xfd0 0xfd4 0xfd8>;
			reg = <0x10001000 0x1000 0x18000000 0x10000 0x18080000 0x8000>;
			interrupts = <0x00 0x99 0x08>;
		};

		consys@18070000 {
			compatible = "mediatek,mt6580-consys";
			reg = <0x18070000 0x200 0x10007000 0x100 0x10000000 0x2000 0x10006000 0x1000 0x10005000 0x1000>;
			interrupts = <0x00 0x9a 0x08 0x00 0x9c 0x08>;
			vcn18-supply = <0x19>;
			vcn28-supply = <0x1a>;
			vcn33_bt-supply = <0x1b>;
			vcn33_wifi-supply = <0x1c>;
			pinctrl-names = "default\0gps_lna_state_init\0gps_lna_state_oh\0gps_lna_state_ol";
			pinctrl-0 = <0x1d>;
			pinctrl-1 = <0x1e>;
			pinctrl-2 = <0x1f>;
			pinctrl-3 = <0x20>;
			status = "okay";
			linux,phandle = <0x8d>;
			phandle = <0x8d>;
		};

		WIFI@0x180F0000 {
			compatible = "mediatek,WIFI";
			reg = <0x180f0000 0x5c>;
			interrupts = <0x00 0x9b 0x08>;
		};

		DISP_PWM@0x1100F000 {
			compatible = "mediatek,DISP_PWM";
			reg = <0x1100f000 0x1000>;
			interrupts = <0x00 0x21 0x08>;
		};

		USB0@0x11100000 {
			compatible = "mediatek,USB0";
			cell-index = <0x00>;
			reg = <0x11100000 0x10000 0x11110000 0x10000>;
			interrupts = <0x00 0x20 0x08>;
			mode = <0x02>;
			multipoint = <0x01>;
			dyn_fifo = <0x01>;
			soft_con = <0x01>;
			dma = <0x01>;
			num_eps = <0x10>;
			dma_channels = <0x08>;
			iddig_gpio = <0x00 0x01>;
			drvvbus_gpio = <0x4c 0x06>;
			pinctrl-names = "usb_default\0iddig_irq_init";
			pinctrl-0 = <0x21>;
			pinctrl-1 = <0x22>;
			status = "okay";
			linux,phandle = <0x8e>;
			phandle = <0x8e>;

			usbiddig {
				compatible = "mediatek,usb_iddig_eint";
				interrupt-parent = <0x0c>;
				interrupts = <0x00 0x08>;
				debounce = <0x00 0x00>;
				status = "okay";
				linux,phandle = <0x8f>;
				phandle = <0x8f>;
			};
		};

		usbphy@0 {
			compatible = "usb-nop-xceiv";
			linux,phandle = <0x90>;
			phandle = <0x90>;
		};

		audio@11140000 {
			compatible = "mediatek,audio";
			reg = <0x11140000 0x10000>;
			interrupts = <0x00 0x50 0x08>;
		};

		mt_soc_dl1_pcm@11140000 {
			compatible = "mediatek,mt_soc_pcm_dl1";
			reg = <0x11140000 0x1000>;
			interrupts = <0x00 0x50 0x08>;
			audclk-gpio = <0x1a 0x00>;
			audmiso-gpio = <0x1c 0x00>;
			audmosi-gpio = <0x1b 0x00>;
			pinctrl-names = "default\0audpmicclk-mode0\0audpmicclk-mode1";
			pinctrl-0 = <0x23>;
			pinctrl-1 = <0x24>;
			pinctrl-2 = <0x25>;
			status = "okay";
			linux,phandle = <0x91>;
			phandle = <0x91>;
		};

		mt_soc_ul1_PCM {
			compatible = "mediatek,mt_soc_pcm_capture";
		};

		mt_soc_voice_md1 {
			compatible = "mediatek,mt_soc_pcm_voice_md1";
		};

		mt_soc_hdmi_pcm {
			compatible = "mediatek,mt_soc_pcm_hdmi";
		};

		mt_soc_uldlloopback_pcm {
			compatible = "mediatek,mt_soc_pcm_uldlloopback";
		};

		mt_soc_i2s0_pcm {
			compatible = "mediatek,mt_soc_pcm_dl1_i2s0";
		};

		mt_soc_mrgrx_pcm {
			compatible = "mediatek,mt_soc_pcm_mrgrx";
		};

		mt_soc_mrgrx_awb_pcm {
			compatible = "mediatek,mt_soc_pcm_mrgrx_awb";
		};

		mt_soc_fm_i2s_pcm {
			compatible = "mediatek,mt_soc_pcm_fm_i2s";
		};

		mt_soc_fm_i2s_awb_pcm {
			compatible = "mediatek,mt_soc_pcm_fm_i2s_awb";
		};

		mt_soc_i2s0dl1_pcm {
			compatible = "mediatek,mt_soc_pcm_dl1_i2s0Dl1";
		};

		mt_soc_deep_buffer_dl_pcm {
			compatible = "mediatek,mt_soc_pcm_deep_buffer_dl";
		};

		mt_soc_dl1_awb_pcm {
			compatible = "mediatek,mt_soc_pcm_dl1_awb";
		};

		mt_soc_voice_md1_bt {
			compatible = "mediatek,mt_soc_pcm_voice_md1_bt";
		};

		mt_soc_voip_bt_out {
			compatible = "mediatek,mt_soc_pcm_dl1_bt";
		};

		mt_soc_voip_bt_in {
			compatible = "mediatek,mt_soc_pcm_bt_dai";
		};

		mt_soc_tdmrx_pcm {
			compatible = "mediatek,mt_soc_tdm_capture";
		};

		mt_soc_fm_mrgtx_pcm {
			compatible = "mediatek,mt_soc_pcm_fmtx";
		};

		mt_soc_ul2_pcm {
			compatible = "mediatek,mt_soc_pcm_capture2";
		};

		mt_soc_i2s0_awb_pcm {
			compatible = "mediatek,mt_soc_pcm_i2s0_awb";
		};

		mt_soc_voice_md2 {
			compatible = "mediatek,mt_soc_pcm_voice_md2";
		};

		mt_soc_routing_pcm {
			compatible = "mediatek,mt_soc_pcm_routing";
		};

		mt_soc_voice_md2_bt {
			compatible = "mediatek,mt_soc_pcm_voice_md2_bt";
		};

		mt_soc_hp_impedance_pcm {
			compatible = "mediatek,Mt_soc_pcm_hp_impedance";
		};

		mt_soc_codec_name {
			compatible = "mediatek,mt_soc_codec_63xx";
		};

		mt_soc_dummy_pcm {
			compatible = "mediatek,mt_soc_pcm_dummy";
		};

		mt_soc_codec_dummy_name {
			compatible = "mediatek,mt_soc_codec_dummy";
		};

		mt_soc_routing_dai_name {
			compatible = "mediatek,mt_soc_dai_routing";
		};

		mt_soc_dai_name {
			compatible = "mediatek,mt_soc_dai_stub";
		};

		mt_soc_dl2_pcm {
			compatible = "mediatek,mt_soc_pcm_dl2";
		};

		AHB_MOM@0x11150000 {
			compatible = "mediatek,AHB_MOM";
			reg = <0x11150000 0x10000>;
		};

		MDI@0x11160000 {
			compatible = "mediatek,MDI";
			reg = <0x11160000 0x10000>;
		};

		G3D_CONFIG@0x13000000 {
			compatible = "mediatek,G3D_CONFIG";
			reg = <0x13000000 0x1000>;
		};

		MALI@0x13010000 {
			compatible = "mediatek,MALI";
			reg = <0x13010000 0x10000>;
		};

		mmsys_config@14000000 {
			compatible = "mediatek,mmsys_config";
			reg = <0x14000000 0x1000>;
			interrupts = <0x00 0x84 0x08>;
		};

		mdp_rdma@14001000 {
			compatible = "mediatek,mdp_rdma";
			reg = <0x14001000 0x1000>;
			interrupts = <0x00 0x71 0x08>;
		};

		mdp_rsz0@14002000 {
			compatible = "mediatek,mdp_rsz0";
			reg = <0x14002000 0x1000>;
			interrupts = <0x00 0x72 0x08>;
		};

		mdp_rsz1@14003000 {
			compatible = "mediatek,mdp_rsz1";
			reg = <0x14003000 0x1000>;
			interrupts = <0x00 0x73 0x08>;
		};

		mdp_wdma@14004000 {
			compatible = "mediatek,mdp_wdma";
			reg = <0x14004000 0x1000>;
			interrupts = <0x00 0x75 0x08>;
		};

		mdp_wrot@14005000 {
			compatible = "mediatek,mdp_wrot";
			reg = <0x14005000 0x1000>;
			interrupts = <0x00 0x76 0x08>;
		};

		mdp_tdshp@14006000 {
			compatible = "mediatek,mdp_tdshp";
			reg = <0x14006000 0x1000>;
			interrupts = <0x00 0x74 0x08>;
		};

		lcm {
			compatible = "mediatek,mt6580-lcm";
			linux,phandle = <0x92>;
			phandle = <0x92>;
		};

		nfc {
			compatible = "mediatek,nfc-gpio-v2";
			gpio-ven = <0x0b>;
			gpio-rst = <0x0a>;
			gpio-eint = <0x0c>;
			gpio-irq = <0x09>;
			linux,phandle = <0x93>;
			phandle = <0x93>;
		};

		DISPSYS@0x14007000 {
			compatible = "mediatek,DISPSYS";
			reg = <0x14000000 0x1000 0x14007000 0x1000 0x14008000 0x1000 0x14009000 0x1000 0x1400a000 0x1000 0x1400b000 0x1000 0x1400c000 0x1000 0x1400d000 0x1000 0x1400e000 0x1000 0x1400f000 0x1000 0x14010000 0x1000 0x14011000 0x1000 0x14012000 0x1000 0x14013000 0x1000 0x1100f000 0x1000 0x14015000 0x1000 0x14016000 0x1000 0x14017000 0x1000 0x14018000 0x1000>;
			interrupts = <0x00 0x00 0x08 0x00 0x77 0x08 0x00 0x00 0x08 0x00 0x79 0x08 0x00 0x00 0x08 0x00 0x7b 0x08 0x00 0x7c 0x08 0x00 0x00 0x08 0x00 0x7e 0x08 0x00 0x7f 0x08 0x00 0x80 0x08 0x00 0x00 0x08 0x00 0x82 0x08 0x00 0x00 0x08 0x00 0x00 0x08 0x00 0x70 0x08 0x00 0x00 0x08 0x00 0x00 0x08 0x00 0x00 0x08>;
		};

		DISP_OVL0@0x14007000 {
			compatible = "mediatek,DISP_OVL0";
			reg = <0x14007000 0x1000>;
			interrupts = <0x00 0x77 0x08>;
		};

		DISP_OVL1@0x14008000 {
			compatible = "mediatek,DISP_OVL1";
			reg = <0x14008000 0x1000>;
		};

		DISP_RDMA0@0x14009000 {
			compatible = "mediatek,DISP_RDMA0";
			reg = <0x14009000 0x1000>;
			interrupts = <0x00 0x79 0x08>;
		};

		DISP_RDMA1@0x1400A000 {
			compatible = "mediatek,DISP_RDMA1";
			reg = <0x1400a000 0x1000>;
		};

		DISP_WDMA@0x1400B000 {
			compatible = "mediatek,DISP_WDMA";
			reg = <0x1400b000 0x1000>;
			interrupts = <0x00 0x7b 0x08>;
		};

		DISP_COLOR@0x1400C000 {
			compatible = "mediatek,DISP_COLOR";
			reg = <0x1400c000 0x1000>;
			interrupts = <0x00 0x7c 0x08>;
		};

		DISP_CCORR@0x1400D000 {
			compatible = "mediatek,DISP_CCORR";
			reg = <0x1400d000 0x1000>;
		};

		DISP_AAL@0x1400E000 {
			compatible = "mediatek,DISP_AAL";
			reg = <0x1400e000 0x1000>;
			interrupts = <0x00 0x7e 0x08>;
		};

		DISP_GAMMA@0x1400F000 {
			compatible = "mediatek,DISP_GAMMA";
			reg = <0x1400f000 0x1000>;
			interrupts = <0x00 0x7f 0x08>;
		};

		DISP_DITHER@0x14010000 {
			compatible = "mediatek,DISP_DITHER";
			reg = <0x14010000 0x1000>;
			interrupts = <0x00 0x80 0x08>;
		};

		DISP_UFOE@0x14011000 {
			compatible = "mediatek,DISP_UFOE";
			reg = <0x14011000 0x1000>;
		};

		DSI@0x14012000 {
			compatible = "mediatek,DSI";
			reg = <0x14012000 0x1000>;
		};

		DPI@0x14013000 {
			compatible = "mediatek,DPI";
			reg = <0x14013000 0x1000>;
		};

		PTP_FSM@0x1100D000 {
			compatible = "mediatek,PTP_FSM";
			reg = <0x1100d000 0x1000>;
			interrupts = <0x00 0x2b 0x08>;
		};

		MM_MUTEX@0x14015000 {
			compatible = "mediatek,MM_MUTEX";
			reg = <0x14015000 0x1000>;
			interrupts = <0x00 0x70 0x08>;
		};

		SMI_LARB0@0x14016000 {
			compatible = "mediatek,SMI_LARB0";
			reg = <0x14016000 0x1000>;
			interrupts = <0x00 0x85 0x08>;
		};

		SMI_COMMON@0x14017000 {
			compatible = "mediatek,SMI_COMMON";
			reg = <0x14017000 0x1000 0x14016000 0x1000 0x15001000 0x1000>;
		};

		MIPI_TX_CONFIG@0x14018000 {
			compatible = "mediatek,MIPI_TX_CONFIG";
			reg = <0x14018000 0x1000>;
		};

		ISPSYS@0x15000000 {
			compatible = "mediatek,ISPSYS";
			reg = <0x15004000 0x9000 0x15000000 0x10000 0x10011000 0x4000 0x10017000 0x1000>;
			interrupts = <0x00 0x8e 0x08 0x00 0x8b 0x08>;
		};

		ISP_SYSR@0x15000000 {
			compatible = "mediatek,ISP_SYSR";
		};

		ISP_PIPEM@0x15000000 {
			compatible = "mediatek,ISP_PIPEM";
		};

		kd_camera_hw1@15008000 {
			compatible = "mediatek,camera_hw";
			reg = <0x15008000 0x1000>;
			vcama-supply = <0x26>;
			vcamd-supply = <0x27>;
			vcamaf-supply = <0x28>;
			vcamio-supply = <0x29>;
			pinctrl-names = "default\0cam0_rst0\0cam0_rst1\0cam0_pnd0\0cam0_pnd1\0cam1_rst0\0cam1_rst1\0cam1_pnd0\0cam1_pnd1\0cam_ldo0_0\0cam_ldo0_1\0cam1_gpio_serial\0cam1_gpio_mipi\0cam_mclk1_enable\0cam_mclk1_disable\0cam_mclk2_enable\0cam_mclk2_disable";
			pinctrl-0 = <0x2a>;
			pinctrl-1 = <0x2b>;
			pinctrl-2 = <0x2c>;
			pinctrl-3 = <0x2d>;
			pinctrl-4 = <0x2e>;
			pinctrl-5 = <0x2f>;
			pinctrl-6 = <0x30>;
			pinctrl-7 = <0x31>;
			pinctrl-8 = <0x32>;
			pinctrl-9 = <0x33>;
			pinctrl-10 = <0x34>;
			pinctrl-11 = <0x35>;
			pinctrl-12 = <0x36>;
			pinctrl-13 = <0x37>;
			pinctrl-14 = <0x38>;
			pinctrl-15 = <0x39>;
			pinctrl-16 = <0x3a>;
			status = "okay";
			vcamd_main2-supply = <0x27>;
			vcamd_sub-supply = <0x27>;
			vcamio_main2-supply = <0x29>;
			vcamio_sub-supply = <0x29>;
			vcama_main2-supply = <0x26>;
			vcama_sub-supply = <0x26>;
			linux,phandle = <0x94>;
			phandle = <0x94>;
		};

		kd_camera_hw2@15008000 {
			compatible = "mediatek,camera_hw2";
			reg = <0x15008000 0x1000>;
			linux,phandle = <0x95>;
			phandle = <0x95>;
		};

		seninf_top@15008000 {
			compatible = "mediatek,SENINF_TOP";
			reg = <0x15008000 0x1000>;
			interrupts = <0x00 0x8e 0x08>;
		};

		CAM_0@0x15004000 {
			compatible = "mediatek,CAM_0";
			reg = <0x15004000 0x1000>;
			interrupts = <0x00 0x8b 0x08>;
		};

		CAM_1@0x15005000 {
			compatible = "mediatek,CAM_1";
			reg = <0x15005000 0x1000>;
		};

		VENC@0x15009000 {
			compatible = "mediatek,VENC";
			reg = <0x15009000 0x1000>;
			interrupts = <0x00 0x8a 0x08>;
		};

		VDEC@0x1500B000 {
			compatible = "mediatek,VDEC";
			reg = <0x1500b000 0x1000>;
			interrupts = <0x00 0x89 0x08>;
		};

		SMI_LARB1@0x15001000 {
			compatible = "mediatek,SMI_LARB1";
			reg = <0x15001000 0x1000>;
			interrupts = <0x00 0x88 0x08>;
		};

		IMGSYS_CONFIG@0x15000000 {
			compatible = "mediatek,IMGSYS_CONFIG";
			reg = <0x15000000 0x1000>;
		};

		hwmsensor@0 {
			compatible = "mediatek,hwmsensor";
		};

		gsensor@0 {
			compatible = "mediatek,gsensor";
		};

		als_ps@0 {
			compatible = "mediatek,als_ps";
			pinctrl-names = "pin_default\0pin_cfg";
			pinctrl-0 = <0x0e>;
			pinctrl-1 = <0x0f>;
			status = "okay";
			linux,phandle = <0x96>;
			phandle = <0x96>;
		};

		m_acc_pl@0 {
			compatible = "mediatek,m_acc_pl";
		};

		m_alsps_pl@0 {
			compatible = "mediatek,m_alsps_pl";
		};

		sensorHub@0 {
			compatible = "mediatek,sensorHub";
		};

		shf@0 {
			compatible = "mediatek,shf";
		};

		m_batch_pl@0 {
			compatible = "mediatek,m_batch_pl";
		};

		gyroscope@0 {
			compatible = "mediatek,gyroscope";
			interrupt-parent = <0x0c>;
			interrupts = <0x01 0x08>;
			debounce = <0x01 0x00>;
			status = "okay";
			linux,phandle = <0x97>;
			phandle = <0x97>;
		};

		m_gyro_pl@0 {
			compatible = "mediatek,m_gyro_pl";
		};

		barometer@0 {
			compatible = "mediatek,barometer";
		};

		m_baro_pl@0 {
			compatible = "mediatek,m_baro_pl";
		};

		msensor@0 {
			compatible = "mediatek,msensor";
		};

		m_mag_pl@0 {
			compatible = "mediatek,m_mag_pl";
		};

		orientation@0 {
			compatible = "mediatek,orientation";
		};

		pedometer@0 {
			compatible = "mediatek,pedometer";
		};

		m_pdr_pl@0 {
			compatible = "mediatek,m_pdr_pl";
		};

		step_counter@0 {
			compatible = "mediatek,step_counter";
		};

		m_step_c_pl@0 {
			compatible = "mediatek,m_step_c_pl";
		};

		in_pocket@0 {
			compatible = "mediatek,in_pocket";
		};

		m_inpk_pl@0 {
			compatible = "mediatek,m_inpk_pl";
		};

		shake@0 {
			compatible = "mediatek,shake";
		};

		m_shk_pl@0 {
			compatible = "mediatek,m_shk_pl";
		};

		face_down@0 {
			compatible = "mediatek,face_down";
		};

		m_fdn_pl@0 {
			compatible = "mediatek,m_fdn_pl";
		};

		activity@0 {
			compatible = "mediatek,activity";
		};

		m_act_pl@0 {
			compatible = "mediatek,m_act_pl";
		};

		heart_rate@0 {
			compatible = "mediatek,heart_rate";
		};

		m_hrm_pl@0 {
			compatible = "mediatek,m_hrm_pl";
		};

		tilt_detector@0 {
			compatible = "mediatek,tilt_detector";
		};

		m_tilt_pl@0 {
			compatible = "mediatek,m_tilt_pl";
		};

		wake_gesture@0 {
			compatible = "mediatek,wake_gesture";
		};

		m_wag_pl@0 {
			compatible = "mediatek,m_wag_pl";
		};

		glance_gesture@0 {
			compatible = "mediatek,glance_gesture";
		};

		m_glg_pl@0 {
			compatible = "mediatek,m_glg_pl";
		};

		pick_up@0 {
			compatible = "mediatek,pick_up";
		};

		m_pkup_pl@0 {
			compatible = "mediatek,m_pkup_pl";
		};

		als {
			compatible = "mediatek, als-eint";
			linux,phandle = <0x98>;
			phandle = <0x98>;
		};

		mtkfb@0 {
			compatible = "mediatek,mtkfb";
			pinctrl-names = "default\0mode_te_gpio\0mode_te_te\0lcm_rst_out0_gpio\0lcm_rst_out1_gpio\0pwm_test_pin_mux_gpio66";
			pinctrl-0 = <0x3b>;
			pinctrl-1 = <0x3c>;
			pinctrl-2 = <0x3d>;
			pinctrl-3 = <0x3e>;
			pinctrl-4 = <0x3f>;
			pinctrl-5 = <0x40>;
			status = "okay";
			linux,phandle = <0x99>;
			phandle = <0x99>;
		};

		dsi_te {
			compatible = "mediatek, dsi_te-eint";
			interrupt-parent = <0x0c>;
			interrupts = <0x44 0x01>;
			debounce = <0x44 0x00>;
			status = "okay";
			linux,phandle = <0x9a>;
			phandle = <0x9a>;
		};
	};

	MOBICORE {
		compatible = "trustonic,mobicore";
		interrupts = <0x00 0x97 0x01>;
	};

	utos {
		compatible = "microtrust,utos";
		interrupts = <0x00 0x9f 0x01 0x00 0xa0 0x01>;
	};

	mt_pmic_regulator {
		compatible = "mediatek,mt_pmic";

		buck_regulators {
			compatible = "mediatek,mt_pmic_buck_regulators";

			buck_vpa {
				regulator-name = "vpa";
				regulator-min-microvolt = <0x7a120>;
				regulator-max-microvolt = <0x37b1d0>;
				regulator-ramp-delay = <0xc350>;
				regulator-enable-ramp-delay = <0xb4>;
				linux,phandle = <0x9b>;
				phandle = <0x9b>;
			};

			buck_vproc {
				regulator-name = "vproc";
				regulator-min-microvolt = <0xaae60>;
				regulator-max-microvolt = <0x16caf6>;
				regulator-ramp-delay = <0x186a>;
				regulator-enable-ramp-delay = <0xb4>;
				regulator-always-on;
				regulator-boot-on;
				linux,phandle = <0x9c>;
				phandle = <0x9c>;
			};
		};

		ldo_regulators {
			compatible = "mediatek,mt_pmic_ldo_regulators";

			ldo_vcn28 {
				regulator-name = "vcn28";
				regulator-min-microvolt = <0x1b7740>;
				regulator-max-microvolt = <0x2ab980>;
				regulator-enable-ramp-delay = <0x108>;
				regulator-default-on = <0x00>;
				status = "okay";
				linux,phandle = <0x1a>;
				phandle = <0x1a>;
			};

			ldo_vtcxo {
				regulator-name = "vtcxo";
				regulator-min-microvolt = <0x2191c0>;
				regulator-max-microvolt = <0x2191c0>;
				regulator-enable-ramp-delay = <0x6e>;
				linux,phandle = <0x41>;
				phandle = <0x41>;
			};

			ldo_va {
				regulator-name = "va";
				regulator-min-microvolt = <0x1b7740>;
				regulator-max-microvolt = <0x2625a0>;
				regulator-enable-ramp-delay = <0x6e>;
				linux,phandle = <0x42>;
				phandle = <0x42>;
			};

			ldo_vcama {
				regulator-name = "vcama";
				regulator-min-microvolt = <0x16e360>;
				regulator-max-microvolt = <0x2ab980>;
				regulator-enable-ramp-delay = <0x108>;
				regulator-default-on = <0x00>;
				status = "okay";
				linux,phandle = <0x26>;
				phandle = <0x26>;
			};

			ldo_vcn33_bt {
				regulator-name = "vcn33_bt";
				regulator-min-microvolt = <0x325aa0>;
				regulator-max-microvolt = <0x36ee80>;
				regulator-enable-ramp-delay = <0x108>;
				linux,phandle = <0x1b>;
				phandle = <0x1b>;
			};

			ldo_vcn33_wifi {
				regulator-name = "vcn33_wifi";
				regulator-min-microvolt = <0x325aa0>;
				regulator-max-microvolt = <0x36ee80>;
				regulator-enable-ramp-delay = <0x108>;
				linux,phandle = <0x1c>;
				phandle = <0x1c>;
			};

			ldo_vio28 {
				regulator-name = "vio28";
				regulator-min-microvolt = <0x2ab980>;
				regulator-max-microvolt = <0x2ab980>;
				regulator-enable-ramp-delay = <0x108>;
				regulator-boot-on;
				linux,phandle = <0x43>;
				phandle = <0x43>;
			};

			ldo_vsim1 {
				regulator-name = "vsim1";
				regulator-min-microvolt = <0x1b7740>;
				regulator-max-microvolt = <0x2dc6c0>;
				regulator-enable-ramp-delay = <0x108>;
				regulator-default-on = <0x00>;
				status = "okay";
				linux,phandle = <0x44>;
				phandle = <0x44>;
			};

			ldo_vsim2 {
				regulator-name = "vsim2";
				regulator-min-microvolt = <0x1b7740>;
				regulator-max-microvolt = <0x2dc6c0>;
				regulator-enable-ramp-delay = <0x108>;
				regulator-default-on = <0x00>;
				status = "okay";
				linux,phandle = <0x45>;
				phandle = <0x45>;
			};

			ldo_vusb {
				regulator-name = "vusb";
				regulator-min-microvolt = <0x325aa0>;
				regulator-max-microvolt = <0x325aa0>;
				regulator-enable-ramp-delay = <0x108>;
				regulator-boot-on;
				linux,phandle = <0x46>;
				phandle = <0x46>;
			};

			ldo_vgp1 {
				regulator-name = "vgp1";
				regulator-min-microvolt = <0x124f80>;
				regulator-max-microvolt = <0x325aa0>;
				regulator-enable-ramp-delay = <0x108>;
				regulator-default-on = <0x00>;
				status = "okay";
				linux,phandle = <0x10>;
				phandle = <0x10>;
			};

			ldo_vgp2 {
				regulator-name = "vgp2";
				regulator-min-microvolt = <0x124f80>;
				regulator-max-microvolt = <0x2dc6c0>;
				regulator-enable-ramp-delay = <0x108>;
				regulator-default-on = <0x00>;
				status = "okay";
				linux,phandle = <0x47>;
				phandle = <0x47>;
			};

			ldo_vemc_3v3 {
				regulator-name = "vemc_3v3";
				regulator-min-microvolt = <0x2dc6c0>;
				regulator-max-microvolt = <0x325aa0>;
				regulator-enable-ramp-delay = <0x108>;
				regulator-boot-on;
				regulator-default-on = <0x00>;
				status = "okay";
				linux,phandle = <0x48>;
				phandle = <0x48>;
			};

			ldo_vcamaf {
				regulator-name = "vcamaf";
				regulator-min-microvolt = <0x124f80>;
				regulator-max-microvolt = <0x325aa0>;
				regulator-enable-ramp-delay = <0x108>;
				regulator-default-on = <0x00>;
				status = "okay";
				linux,phandle = <0x28>;
				phandle = <0x28>;
			};

			ldo_vmc {
				regulator-name = "vmc";
				regulator-min-microvolt = <0x1b7740>;
				regulator-max-microvolt = <0x325aa0>;
				regulator-enable-ramp-delay = <0x2c>;
				regulator-default-on = <0x00>;
				status = "okay";
				linux,phandle = <0x49>;
				phandle = <0x49>;
			};

			ldo_vmch {
				regulator-name = "vmch";
				regulator-min-microvolt = <0x2dc6c0>;
				regulator-max-microvolt = <0x325aa0>;
				regulator-enable-ramp-delay = <0x2c>;
				regulator-default-on = <0x00>;
				status = "okay";
				linux,phandle = <0x4a>;
				phandle = <0x4a>;
			};

			ldo_vibr {
				regulator-name = "vibr";
				regulator-min-microvolt = <0x124f80>;
				regulator-max-microvolt = <0x325aa0>;
				regulator-enable-ramp-delay = <0x2c>;
				regulator-default-on = <0x00>;
				status = "okay";
				linux,phandle = <0x4b>;
				phandle = <0x4b>;
			};

			ldo_vrtc {
				regulator-name = "vrtc";
				regulator-min-microvolt = <0x2ab980>;
				regulator-max-microvolt = <0x2ab980>;
				regulator-enable-ramp-delay = <0x2c>;
				linux,phandle = <0x4c>;
				phandle = <0x4c>;
			};

			ldo_vm {
				regulator-name = "vm";
				regulator-min-microvolt = <0x124f80>;
				regulator-max-microvolt = <0x1b7740>;
				regulator-enable-ramp-delay = <0x108>;
				regulator-boot-on;
				regulator-default-on = <0x00>;
				status = "okay";
				linux,phandle = <0x4d>;
				phandle = <0x4d>;
			};

			ldo_vrf18 {
				regulator-name = "vrf18";
				regulator-min-microvolt = <0x1b7740>;
				regulator-max-microvolt = <0x1b7740>;
				regulator-enable-ramp-delay = <0xdc>;
				regulator-default-on = <0x00>;
				status = "okay";
				linux,phandle = <0x4e>;
				phandle = <0x4e>;
			};

			ldo_vio18 {
				regulator-name = "vio18";
				regulator-min-microvolt = <0x1b7740>;
				regulator-max-microvolt = <0x1b7740>;
				regulator-enable-ramp-delay = <0x108>;
				regulator-boot-on;
				linux,phandle = <0x4f>;
				phandle = <0x4f>;
			};

			ldo_vcamd {
				regulator-name = "vcamd";
				regulator-min-microvolt = <0x124f80>;
				regulator-max-microvolt = <0x1b7740>;
				regulator-enable-ramp-delay = <0x108>;
				regulator-default-on = <0x00>;
				status = "okay";
				linux,phandle = <0x27>;
				phandle = <0x27>;
			};

			ldo_vcamio {
				regulator-name = "vcamio";
				regulator-min-microvolt = <0x1b7740>;
				regulator-max-microvolt = <0x1b7740>;
				regulator-enable-ramp-delay = <0xdc>;
				linux,phandle = <0x50>;
				phandle = <0x50>;
			};

			ldo_vgp3 {
				regulator-name = "vgp3";
				regulator-min-microvolt = <0x124f80>;
				regulator-max-microvolt = <0x1b7740>;
				regulator-enable-ramp-delay = <0x108>;
				regulator-default-on = <0x00>;
				status = "okay";
				linux,phandle = <0x51>;
				phandle = <0x51>;
			};

			ldo_vcn_1v8 {
				regulator-name = "vcn_1v8";
				regulator-min-microvolt = <0x1b7740>;
				regulator-max-microvolt = <0x1b7740>;
				regulator-enable-ramp-delay = <0x2c>;
				regulator-default-on = <0x00>;
				status = "okay";
				linux,phandle = <0x19>;
				phandle = <0x19>;
			};

			vcanio_ldo_reg {
				regulator-name = "vcanio";
				regulator-default-on = <0x00>;
				status = "okay";
				linux,phandle = <0x29>;
				phandle = <0x29>;
			};

			vcn33_ldo_reg {
				regulator-name = "vcn33";
				regulator-default-on = <0x00>;
				status = "okay";
				linux,phandle = <0x9d>;
				phandle = <0x9d>;
			};
		};

		regulators_supply {
			compatible = "mediatek,mt_pmic_regulator_supply";
			vcn28-supply = <0x1a>;
			vtcxo-supply = <0x41>;
			va-supply = <0x42>;
			vcn33_bt-supply = <0x1b>;
			vcn33_wifi-supply = <0x1c>;
			vio28-supply = <0x43>;
			vsim1-supply = <0x44>;
			vsim2-supply = <0x45>;
			vusb-supply = <0x46>;
			vgp1-supply = <0x10>;
			vgp2-supply = <0x47>;
			vemc_3v3-supply = <0x48>;
			vcamaf-supply = <0x28>;
			vmc-supply = <0x49>;
			vmch-supply = <0x4a>;
			vibr-supply = <0x4b>;
			vrtc-supply = <0x4c>;
			vm-supply = <0x4d>;
			vrf18-supply = <0x4e>;
			vio18-supply = <0x4f>;
			vcamd-supply = <0x27>;
			vcamio-supply = <0x50>;
			vgp3-supply = <0x51>;
			vcn_1v8-supply = <0x19>;
		};
	};

	rf_clock_buffer {
		compatible = "mediatek,rf_clock_buffer";
		#mediatek,clkbuf-quantity = <0x04>;
		#mediatek,clkbuf-config = <0x02 0x01 0x01 0x01>;
		mediatek,clkbuf-quantity = <0x04>;
		mediatek,clkbuf-config = <0x02 0x02 0x01 0x01>;
		status = "okay";
		linux,phandle = <0x9e>;
		phandle = <0x9e>;
	};

	bq24296 {
		compatible = "mediatek,bq24296";
		pinctrl-names = "default\0drvvbus_low\0drvvbus_high";
		pinctrl-0 = <0x52>;
		pinctrl-1 = <0x53>;
		pinctrl-2 = <0x54>;
		status = "okay";
		linux,phandle = <0x9f>;
		phandle = <0x9f>;
	};

	firmware {

		android {
			compatible = "android,firmware";

			fstab {
				compatible = "android,fstab";

				system {
					compatible = "android,system";
					dev = "/dev/block/platform/mtk-msdc.0/11120000.msdc0/by-name/system";
					type = "ext4";
					mnt_flags = "ro";
					fsmgr_flags = "wait";
				};

				vendor {
					compatible = "android,vendor";
					dev = "/dev/block/platform/mtk-msdc.0/11120000.msdc0/by-name/vendor";
					type = "ext4";
					mnt_flags = "ro";
					fsmgr_flags = "wait";
				};
			};
		};
	};

	odm {
		compatible = "simple-bus";
		linux,phandle = <0xa0>;
		phandle = <0xa0>;

		led@0 {
			compatible = "mediatek,red";
			led_mode = <0x04>;
			data = <0x01>;
			pwm_config = <0x00 0x00 0x00 0x00 0x00>;
		};

		led@1 {
			compatible = "mediatek,green";
			led_mode = <0x04>;
			data = <0x01>;
			pwm_config = <0x00 0x00 0x00 0x00 0x00>;
		};

		led@2 {
			compatible = "mediatek,blue";
			led_mode = <0x04>;
			data = <0x01>;
			pwm_config = <0x00 0x00 0x00 0x00 0x00>;
		};

		led@3 {
			compatible = "mediatek,jogball-backlight";
			led_mode = <0x00>;
			data = <0x01>;
			pwm_config = <0x00 0x00 0x00 0x00 0x00>;
		};

		led@4 {
			compatible = "mediatek,keyboard-backlight";
			led_mode = <0x00>;
			data = <0x01>;
			pwm_config = <0x00 0x00 0x00 0x00 0x00>;
		};

		led@5 {
			compatible = "mediatek,button-backlight";
			led_mode = <0x00>;
			data = <0x01>;
			pwm_config = <0x00 0x00 0x00 0x00 0x00>;
		};

		led@6 {
			compatible = "mediatek,lcd-backlight";
			led_mode = <0x05>;
			data = <0x01>;
			pwm_config = <0x00 0x00 0x00 0x00 0x00>;
		};

		vibrator@0 {
			compatible = "mediatek,vibrator";
			vib_timer = <0x19>;
			vib_limit = <0x09>;
			vib_vol = <0x06>;
			linux,phandle = <0xa1>;
			phandle = <0xa1>;
		};

		cust_accel@0 {
			compatible = "mediatek,mc3410";
			i2c_num = <0x02>;
			i2c_addr = <0x4c 0x00 0x00 0x00>;
			direction = <0x05>;
			power_id = <0xffff>;
			power_vol = <0x00>;
			firlen = <0x00>;
			is_batch_supported = <0x00>;
		};

		cust_accel@1 {
			compatible = "mediatek,n2dm";
			i2c_num = <0x02>;
			i2c_addr = <0x08 0x00 0x00 0x00>;
			direction = <0x07>;
			power_id = <0xffff>;
			power_vol = <0x00>;
			firlen = <0x00>;
			is_batch_supported = <0x00>;
		};

		cust_accel@2 {
			compatible = "mediatek,mpu6500g";
			i2c_num = <0x02>;
			i2c_addr = <0x68 0x00 0x00 0x00>;
			direction = <0x06>;
			power_id = <0xffff>;
			power_vol = <0x00>;
			firlen = <0x00>;
			is_batch_supported = <0x00>;
		};

		cust_accel@3 {
			compatible = "mediatek,lsm6ds3_acc";
			i2c_num = <0x02>;
			i2c_addr = <0x6b 0x00 0x00 0x00>;
			direction = <0x02>;
			power_id = <0xffff>;
			power_vol = <0x00>;
			firlen = <0x00>;
			is_batch_supported = <0x00>;
		};

		cust_alsps@0 {
			compatible = "mediatek,cm36558";
			i2c_num = <0x02>;
			i2c_addr = <0x51 0x00 0x00 0x00>;
			polling_mode_ps = <0x00>;
			polling_mode_als = <0x01>;
			power_id = <0xffff>;
			power_vol = <0x00>;
			als_level = <0x00 0x148 0x35d 0x561 0xc35 0x1e29 0x1e57 0x314d 0x5a16 0x6f0e 0x81fa 0xb80c 0xe15e 0xe15e 0xffff>;
			als_value = <0x00 0x85 0x130 0x1f6 0x3ec 0x7d5 0xbf2 0x138d 0x1f48 0x271a 0x2ee0 0x3e80 0x4e20 0x4e20 0x4e20 0x4e20>;
			ps_threshold_high = <0x1a>;
			ps_threshold_low = <0x15>;
			is_batch_supported_ps = <0x00>;
			is_batch_supported_als = <0x00>;
		};

		cust_alsps@1 {
			compatible = "mediatek,epl259x";
			i2c_num = <0x02>;
			i2c_addr = <0x49 0x00 0x00 0x00>;
			polling_mode_ps = <0x00>;
			polling_mode_als = <0x01>;
			power_id = <0xffff>;
			power_vol = <0x00>;
			als_level = <0x14 0x2d 0x46 0x5a 0x96 0x12c 0x1f4 0x2bc 0x47e 0x8ca 0x1194 0x1f40 0x3a98 0x7530 0xc350>;
			als_value = <0x0a 0x1e 0x3c 0x50 0x64 0xc8 0x190 0x258 0x320 0x5dc 0xbb8 0x1770 0x2710 0x4e20 0x9c40 0xea60>;
			ps_threshold_high = <0x320>;
			ps_threshold_low = <0x1f4>;
			is_batch_supported_ps = <0x00>;
			is_batch_supported_als = <0x00>;
		};

		cust_alsps@2 {
			compatible = "mediatek,stk3x1x";
			i2c_num = <0x02>;
			i2c_addr = <0x48 0x00 0x00 0x00>;
			polling_mode_ps = <0x00>;
			polling_mode_als = <0x01>;
			power_id = <0xffff>;
			power_vol = <0x00>;
			als_level = <0x0d 0x14 0x24 0x3b 0x52 0x84 0xcd 0x111 0x1f4 0x34d 0x470 0x609 0x93c 0x122f 0x1b46>;
			als_value = <0x00 0x0a 0x32 0x64 0x96 0xc8 0xfa 0x1c2 0x2bc 0x3a2 0x4e2 0x6a4 0xa28 0x1400 0x1e00 0x2800>;
			ps_threshold_high = <0x6a4>;
			ps_threshold_low = <0x5dc>;
			is_batch_supported_ps = <0x00>;
			is_batch_supported_als = <0x00>;
		};

		cust_mag@0 {
			compatible = "mediatek,af8133x";
			i2c_num = <0x02>;
			i2c_addr = <0x1e 0x00 0x00 0x00>;
			direction = <0x03>;
			power_id = <0xffff>;
			power_vol = <0x00>;
			is_batch_supported = <0x00>;
		};

		cust_mag@1 {
			compatible = "mediatek,st480";
			i2c_num = <0x02>;
			i2c_addr = <0x0c 0x00 0x00 0x00>;
			direction = <0x01>;
			power_id = <0xffff>;
			power_vol = <0x00>;
			is_batch_supported = <0x00>;
		};

		cust_gyro@0 {
			compatible = "mediatek,itg1010";
			i2c_num = <0x02>;
			direction = <0x05>;
			power_id = <0xffff>;
			power_vol = <0x00>;
			firlen = <0x00>;
			is_batch_supported = <0x00>;
		};

		cust_gyro@1 {
			compatible = "mediatek,mpu6050gy";
			i2c_num = <0x02>;
			i2c_addr = <0x69 0x00 0x00 0x00>;
			direction = <0x06>;
			power_id = <0xffff>;
			power_vol = <0x00>;
			firlen = <0x00>;
			is_batch_supported = <0x00>;
		};

		cust_gyro@2 {
			compatible = "mediatek,lsm6ds3_gyro";
			i2c_num = <0x01>;
			i2c_addr = <0x6b 0x00 0x00 0x00>;
			direction = <0x02>;
			power_id = <0xffff>;
			power_vol = <0x00>;
			firlen = <0x00>;
			is_batch_supported = <0x00>;
		};

		cust_gyro@3 {
			compatible = "mediatek,mpu6500gy";
			i2c_num = <0x02>;
			i2c_addr = <0x68 0x00 0x00 0x00>;
			direction = <0x06>;
			power_id = <0xffff>;
			power_vol = <0x00>;
			firlen = <0x00>;
			is_batch_supported = <0x00>;
		};

		cust_baro@0 {
			compatible = "mediatek,bmp280new";
			i2c_num = <0x01>;
			direction = <0x00>;
			power_id = <0xffff>;
			power_vol = <0x00>;
			firlen = <0x20>;
			is_batch_supported = <0x00>;
		};
	};

	cs_finger@0 {
		compatible = "mediatek,cs_finger";
		linux,phandle = <0xa2>;
		phandle = <0xa2>;
	};

	icnfpsensor@0 {
		compatible = "mediatek,icnfpsensor";
		linux,phandle = <0xa3>;
		phandle = <0xa3>;
	};

	aw9523 {
		compatible = "mediatek,aw9523";
		pinctrl-names = "default\0rstn_h\0rstn_l";
		pinctrl-0 = <0x55>;
		pinctrl-1 = <0x56>;
		pinctrl-2 = <0x57>;
		status = "okay";
		interrupt-parent = <0x0c>;
		interrupts = <0x04 0x08>;
		debounce = <0x04 0x3e80>;
		linux,phandle = <0xa4>;
		phandle = <0xa4>;
	};

	aw9106 {
		compatible = "mediatek,aw9106";
		pinctrl-names = "default\0shutdown_h\0shutdown_l";
		pinctrl-0 = <0x58>;
		pinctrl-1 = <0x59>;
		pinctrl-2 = <0x5a>;
		status = "okay";
		interrupt-parent = <0x0c>;
		interrupts = <0x06 0x08>;
		debounce = <0x06 0x3e80>;
		linux,phandle = <0xa5>;
		phandle = <0xa5>;
	};

	remote_ctrl {
		compatible = "mediatek,remote";
		pinctrl-names = "default\0remote_eint_in\0remote_eint1\0remote_eint0\0remote_rst1\0remote_rst0\0remote_vdd_gpio_1\0remote_vdd_gpio_0";
		pinctrl-0 = <0x5b>;
		pinctrl-1 = <0x5c>;
		pinctrl-2 = <0x5d>;
		pinctrl-3 = <0x5e>;
		pinctrl-4 = <0x5f>;
		pinctrl-5 = <0x60>;
		pinctrl-6 = <0x61>;
		pinctrl-7 = <0x62>;
		status = "okay";
		linux,phandle = <0xa6>;
		phandle = <0xa6>;
	};

	trusty {
		compatible = "android,trusty-smc-v1";
		ranges;
		#address-cells = <0x02>;
		#size-cells = <0x02>;

		irq {
			compatible = "android,trusty-irq-v1";
			ppi-interrupt-parent = <0x01>;
		};

		log {
			compatible = "android,trusty-log-v1";
		};

		virtio {
			compatible = "android,trusty-virtio-v1";
		};

		mtee {
			compatible = "mediatek,trusty-mtee-v1";
		};
	};

	__symbols__ {
		chosen = "/chosen";
		mmc0 = "/mtk-msdc.0/msdc0@11120000";
		mmc1 = "/mtk-msdc.0/msdc1@11130000";
		msdc1_ins = "/mtk-msdc.0/default";
		cpu0 = "/cpus/cpu@0";
		cpu1 = "/cpus/cpu@1";
		cpu2 = "/cpus/cpu@2";
		cpu3 = "/cpus/cpu@3";
		reserved_memory = "/reserved-memory";
		gic = "/interrupt-controller@10210000";
		bus = "/bus";
		bat_meter = "/bus/bat_meter";
		bat_comm = "/bus/bat_comm";
		keypad = "/bus/keypad@10002000";
		gpio_usage_mapping = "/bus/gpio";
		gpio = "/bus/gpio@0x10005000";
		cpu_dbgapb = "/bus/cpu_dbgapb@10170000";
		eintc = "/bus/eintc@1000b000";
		ap_ccif0 = "/bus/ap_ccif0@1000C000";
		mcucfg = "/bus/mcucfg@10200000";
		sys_cirq = "/bus/sys_cirq@10202000";
		ap_dma = "/bus/dma@0x11000000";
		auxadc = "/bus/adc_hw@11003000";
		syscfg_pctl_a = "/bus/syscfg_pctl_a@0x10005000";
		pio = "/bus/pinctrl@0x10005000";
		mmc0_pins_default = "/bus/pinctrl@0x10005000/mmc0@default";
		mmc0_register_setting_default = "/bus/pinctrl@0x10005000/mmc0@register_default";
		mmc1_pins_default = "/bus/pinctrl@0x10005000/mmc1@default";
		mmc1_pins_insert_default = "/bus/pinctrl@0x10005000/mmc1_ins_default";
		mmc1_pins_insert_cfg = "/bus/pinctrl@0x10005000/mmc1_ins_cfg";
		mmc1_pins_sdr104 = "/bus/pinctrl@0x10005000/mmc1@sdr104";
		mmc1_pins_sdr50 = "/bus/pinctrl@0x10005000/mmc1@sdr50";
		mmc1_pins_ddr50 = "/bus/pinctrl@0x10005000/mmc1@ddr50";
		mmc1_register_setting_default = "/bus/pinctrl@0x10005000/mmc1@register_default";
		alsps_intpin_cfg = "/bus/pinctrl@0x10005000/alspspincfg";
		alsps_intpin_default = "/bus/pinctrl@0x10005000/alspsdefaultcfg";
		ACCDET_pins_default = "/bus/pinctrl@0x10005000/eint0default";
		ACCDET_pins_eint_as_int = "/bus/pinctrl@0x10005000/eint@0";
		ctp_pins_default = "/bus/pinctrl@0x10005000/toucheint5default";
		ctp_pins_eint_as_int = "/bus/pinctrl@0x10005000/toucheint@5";
		ctp_pins_eint_output0 = "/bus/pinctrl@0x10005000/eintoutput0";
		ctp_pins_eint_output1 = "/bus/pinctrl@0x10005000/eintoutput1";
		ctp_pins_rst_output0 = "/bus/pinctrl@0x10005000/rstoutput0";
		ctp_pins_rst_output1 = "/bus/pinctrl@0x10005000/rstoutput1";
		AUD_pins_default = "/bus/pinctrl@0x10005000/audiodefault";
		AUD_pins_pmicclk_mode0 = "/bus/pinctrl@0x10005000/pmicclkmode0";
		AUD_pins_pmicclk_mode1 = "/bus/pinctrl@0x10005000/pmicclkmode1";
		mtkfb_pins_mode_te_gpio = "/bus/pinctrl@0x10005000/mode_te_gpio";
		mtkfb_pins_mode_te_te = "/bus/pinctrl@0x10005000/mode_te_te";
		mtkfb_pins_lcm_reset0 = "/bus/pinctrl@0x10005000/lcm_rst_out0_gpio";
		mtkfb_pins_lcm_reset1 = "/bus/pinctrl@0x10005000/lcm_rst_out1_gpio";
		mtkfb_pins_pwm_test_pin_mux_gpio66 = "/bus/pinctrl@0x10005000/pwm_test_pin_mux_gpio66";
		mtkfb_pins_default = "/bus/pinctrl@0x10005000/mtkfb_default";
		camera_pins_cam0_rst0 = "/bus/pinctrl@0x10005000/cam0@0";
		camera_pins_cam0_rst1 = "/bus/pinctrl@0x10005000/cam0@1";
		camera_pins_cam0_pnd0 = "/bus/pinctrl@0x10005000/cam0@2";
		camera_pins_cam0_pnd1 = "/bus/pinctrl@0x10005000/cam0@3";
		camera_pins_cam1_rst0 = "/bus/pinctrl@0x10005000/cam1@0";
		camera_pins_cam1_rst1 = "/bus/pinctrl@0x10005000/cam1@1";
		camera_pins_cam1_pnd0 = "/bus/pinctrl@0x10005000/cam1@2";
		camera_pins_cam1_pnd1 = "/bus/pinctrl@0x10005000/cam1@3";
		camera_pins_cam_ldo0_0 = "/bus/pinctrl@0x10005000/cam@0";
		camera_pins_cam_ldo0_1 = "/bus/pinctrl@0x10005000/cam@1";
		camera_pins_default = "/bus/pinctrl@0x10005000/camdefault";
		camera_pins_cam1_gpio_serial = "/bus/pinctrl@0x10005000/cam1serial@0";
		camera_pins_cam1_gpio_mipi = "/bus/pinctrl@0x10005000/cam1mipi@0";
		camera_pins_cam_mclk1_enable = "/bus/pinctrl@0x10005000/mclk1enable@0";
		camera_pins_cam_mclk1_disable = "/bus/pinctrl@0x10005000/mclk1disable@0";
		camera_pins_cam_mclk2_enable = "/bus/pinctrl@0x10005000/mclk2enable@0";
		camera_pins_cam_mclk2_disable = "/bus/pinctrl@0x10005000/mclk2disable@0";
		consys_pins_default = "/bus/pinctrl@0x10005000/consys_default";
		gpslna_pins_init = "/bus/pinctrl@0x10005000/gpslna@0";
		gpslna_pins_oh = "/bus/pinctrl@0x10005000/gpslna@1";
		gpslna_pins_ol = "/bus/pinctrl@0x10005000/gpslna@2";
		aw9523_pin_default = "/bus/pinctrl@0x10005000/aw@0";
		aw9523_rstn_h = "/bus/pinctrl@0x10005000/aw@1";
		aw9523_rstn_l = "/bus/pinctrl@0x10005000/aw@2";
		www_pin_default = "/bus/pinctrl@0x10005000/www@0";
		www_shutdown_h = "/bus/pinctrl@0x10005000/www@1";
		www_shutdown_l = "/bus/pinctrl@0x10005000/www@2";
		remote_ctrl_default = "/bus/pinctrl@0x10005000/default";
		remote_ctrl_eint_in = "/bus/pinctrl@0x10005000/eint_in@0";
		remote_ctrl_eint_h = "/bus/pinctrl@0x10005000/eint_out@1";
		remote_ctrl_eint_l = "/bus/pinctrl@0x10005000/eint_out@2";
		remote_ctrl_rst_h = "/bus/pinctrl@0x10005000/rst_out@0";
		remote_ctrl_rst_l = "/bus/pinctrl@0x10005000/rst_out@1";
		remote_ctrl_vdd_en_h = "/bus/pinctrl@0x10005000/vdd_en@0";
		remote_ctrl_vdd_en_l = "/bus/pinctrl@0x10005000/vdd_en@1";
		bq24296_pin_default = "/bus/pinctrl@0x10005000/bq24296_default";
		gpio76_mode0_drvvbus_low = "/bus/pinctrl@0x10005000/drvvbus_low";
		gpio76_mode0_drvvbus_high = "/bus/pinctrl@0x10005000/drvvbus_high";
		usb_default = "/bus/pinctrl@0x10005000/usb_default";
		gpio0_mode1_iddig = "/bus/pinctrl@0x10005000/iddig_irq_init";
		i2c0 = "/bus/i2c@11009000";
		bq24296_mtk = "/bus/i2c@11009000/bq24296@6b";
		camera_main_mtk = "/bus/i2c@11009000/camera_main@12";
		camera_sub_mtk = "/bus/i2c@11009000/camera_sub@14";
		remote_ctrl_mtk = "/bus/i2c@11009000/remote_ctrl@10";
		i2c1 = "/bus/i2c@1100a000";
		cap_touch_mtk = "/bus/i2c@1100a000/cap_touch@38";
		ext_gpio_aw9523_mtk = "/bus/i2c@1100a000/ext_gpio_aw9523@5b";
		i2c2 = "/bus/i2c@1100b000";
		gsensor_mtk = "/bus/i2c@1100b000/gsensor@68";
		alsps_mtk = "/bus/i2c@1100b000/alsps@63";
		msensor_mtk = "/bus/i2c@1100b000/msensor@0c";
		gyro_mtk = "/bus/i2c@1100b000/gyro@69";
		ext_gpio_aw9106_mtk = "/bus/i2c@1100b000/ext_gpio_aw9106@5b";
		touch = "/bus/touch@0";
		accdet = "/bus/accdet";
		remoteir = "/bus/remoteir";
		gse_1 = "/bus/gse_1";
		btif_tx = "/bus/btif_tx@11000380";
		btif_rx = "/bus/btif_rx@11000400";
		btif = "/bus/btif@1100e000";
		consys = "/bus/consys@18070000";
		usb0 = "/bus/USB0@0x11100000";
		otg_iddig = "/bus/USB0@0x11100000/usbiddig";
		usbphy0 = "/bus/usbphy@0";
		audgpio = "/bus/mt_soc_dl1_pcm@11140000";
		lcm = "/bus/lcm";
		nfc = "/bus/nfc";
		kd_camera_hw1 = "/bus/kd_camera_hw1@15008000";
		kd_camera_hw2 = "/bus/kd_camera_hw2@15008000";
		alsps = "/bus/als_ps@0";
		gyro = "/bus/gyroscope@0";
		als = "/bus/als";
		mtkfb = "/bus/mtkfb@0";
		dsi_te = "/bus/dsi_te";
		mt_pmic_vpa_buck_reg = "/mt_pmic_regulator/buck_regulators/buck_vpa";
		mt_pmic_vproc_buck_reg = "/mt_pmic_regulator/buck_regulators/buck_vproc";
		mt_pmic_vcn28_ldo_reg = "/mt_pmic_regulator/ldo_regulators/ldo_vcn28";
		mt_pmic_vtcxo_ldo_reg = "/mt_pmic_regulator/ldo_regulators/ldo_vtcxo";
		mt_pmic_va_ldo_reg = "/mt_pmic_regulator/ldo_regulators/ldo_va";
		mt_pmic_vcama_ldo_reg = "/mt_pmic_regulator/ldo_regulators/ldo_vcama";
		mt_pmic_vcn33_bt_ldo_reg = "/mt_pmic_regulator/ldo_regulators/ldo_vcn33_bt";
		mt_pmic_vcn33_wifi_ldo_reg = "/mt_pmic_regulator/ldo_regulators/ldo_vcn33_wifi";
		mt_pmic_vio28_ldo_reg = "/mt_pmic_regulator/ldo_regulators/ldo_vio28";
		mt_pmic_vsim1_ldo_reg = "/mt_pmic_regulator/ldo_regulators/ldo_vsim1";
		mt_pmic_vsim2_ldo_reg = "/mt_pmic_regulator/ldo_regulators/ldo_vsim2";
		mt_pmic_vusb_ldo_reg = "/mt_pmic_regulator/ldo_regulators/ldo_vusb";
		mt_pmic_vgp1_ldo_reg = "/mt_pmic_regulator/ldo_regulators/ldo_vgp1";
		mt_pmic_vgp2_ldo_reg = "/mt_pmic_regulator/ldo_regulators/ldo_vgp2";
		mt_pmic_vemc_3v3_ldo_reg = "/mt_pmic_regulator/ldo_regulators/ldo_vemc_3v3";
		mt_pmic_vcamaf_ldo_reg = "/mt_pmic_regulator/ldo_regulators/ldo_vcamaf";
		mt_pmic_vmc_ldo_reg = "/mt_pmic_regulator/ldo_regulators/ldo_vmc";
		mt_pmic_vmch_ldo_reg = "/mt_pmic_regulator/ldo_regulators/ldo_vmch";
		mt_pmic_vibr_ldo_reg = "/mt_pmic_regulator/ldo_regulators/ldo_vibr";
		mt_pmic_vrtc_ldo_reg = "/mt_pmic_regulator/ldo_regulators/ldo_vrtc";
		mt_pmic_vm_ldo_reg = "/mt_pmic_regulator/ldo_regulators/ldo_vm";
		mt_pmic_vrf18_ldo_reg = "/mt_pmic_regulator/ldo_regulators/ldo_vrf18";
		mt_pmic_vio18_ldo_reg = "/mt_pmic_regulator/ldo_regulators/ldo_vio18";
		mt_pmic_vcamd_ldo_reg = "/mt_pmic_regulator/ldo_regulators/ldo_vcamd";
		mt_pmic_vcamio_ldo_reg = "/mt_pmic_regulator/ldo_regulators/ldo_vcamio";
		mt_pmic_vgp3_ldo_reg = "/mt_pmic_regulator/ldo_regulators/ldo_vgp3";
		mt_pmic_vcn_1v8_ldo_reg = "/mt_pmic_regulator/ldo_regulators/ldo_vcn_1v8";
		mt_pmic_vcanio_ldo_reg = "/mt_pmic_regulator/ldo_regulators/vcanio_ldo_reg";
		mt_pmic_vcn33_ldo_reg = "/mt_pmic_regulator/ldo_regulators/vcn33_ldo_reg";
		rf_clock_buffer_ctrl = "/rf_clock_buffer";
		bq24296 = "/bq24296";
		odm = "/odm";
		vibrator0 = "/odm/vibrator@0";
		cs_finger = "/cs_finger@0";
		icnfpsensor = "/icnfpsensor@0";
		aw9523 = "/aw9523";
		aw9106 = "/aw9106";
		remote_ctrl = "/remote_ctrl";
	};
};
